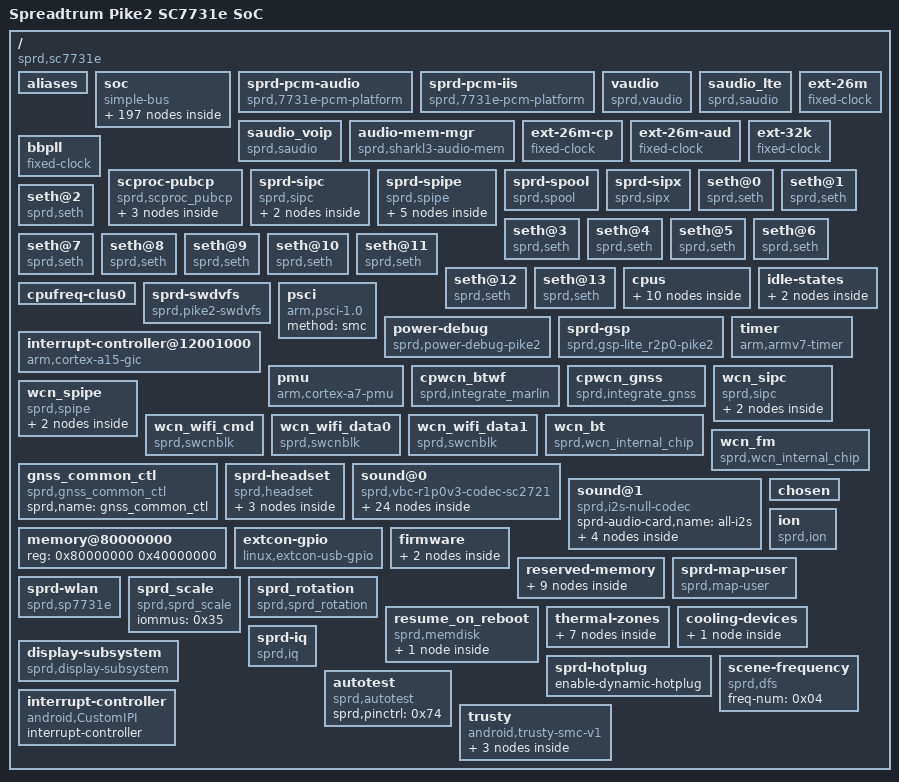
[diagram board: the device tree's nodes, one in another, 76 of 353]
/dts-v1/;

/ {
	interrupt-parent = <0x01>;
	#address-cells = <0x01>;
	#size-cells = <0x01>;
	cpuinfo_hardware = "Unisoc SC7731e";
	model = "Spreadtrum Pike2 SC7731e SoC";
	compatible = "sprd,sc7731e";
	sprd,sc-id = "sp7731e 1000 1000";

	aliases {
		serial0 = "/soc/ap-apb/serial@70000000";
		serial1 = "/soc/ap-apb/serial@70100000";
		i2c0 = "/soc/ap-apb/i2c@70500000";
		i2c1 = "/soc/ap-apb/i2c@70600000";
		i2c2 = "/soc/ap-apb/i2c@70700000";
		spi0 = "/soc/ap-apb/spi@70a00000";
		spi1 = "/soc/ap-apb/spi@70b00000";
		seth0 = "/seth@0";
		seth1 = "/seth@1";
		seth2 = "/seth@2";
		seth3 = "/seth@3";
		seth4 = "/seth@4";
		seth5 = "/seth@5";
		seth6 = "/seth@6";
		seth7 = "/seth@7";
		seth8 = "/seth@8";
		seth9 = "/seth@9";
		seth10 = "/seth@10";
		seth11 = "/seth@11";
		seth12 = "/seth@12";
		seth13 = "/seth@13";
		cooling-device0 = "/cooling-devices/cluster0-cooling";
		thm-sensor11 = "/thermal-zones/cpu-thmzone";
	};

	soc {
		compatible = "simple-bus";
		#address-cells = <0x01>;
		#size-cells = <0x01>;
		ranges;
		phandle = <0x76>;

		syscon@20e00000 {
			compatible = "syscon";
			#syscon-cells = <0x02>;
			reg = <0x20e00000 0x100000>;
			phandle = <0x0e>;
		};

		syscon@33100000 {
			compatible = "syscon";
			#syscon-cells = <0x02>;
			reg = <0x33100000 0x10000>;
			phandle = <0x58>;
		};

		syscon@40200000 {
			compatible = "syscon";
			#syscon-cells = <0x02>;
			reg = <0x40200000 0x10000>;
			phandle = <0x56>;
		};

		syscon@402b0000 {
			compatible = "syscon";
			#syscon-cells = <0x02>;
			reg = <0x402b0000 0x10000>;
			phandle = <0x1b>;
		};

		syscon@402e0000 {
			compatible = "syscon";
			#syscon-cells = <0x02>;
			reg = <0x402e0000 0x10000>;
			phandle = <0x11>;
		};

		syscon@40350000 {
			compatible = "syscon";
			#syscon-cells = <0x02>;
			reg = <0x40350000 0x3000>;
			phandle = <0x77>;
		};

		syscon@40353000 {
			compatible = "syscon";
			#syscon-cells = <0x02>;
			reg = <0x40353000 0x3000>;
			phandle = <0x78>;
		};

		syscon@40356000 {
			compatible = "syscon";
			#syscon-cells = <0x02>;
			reg = <0x40356000 0x3000>;
			phandle = <0x79>;
		};

		syscon@40359000 {
			compatible = "syscon";
			#syscon-cells = <0x02>;
			reg = <0x40359000 0x3000>;
			phandle = <0x7a>;
		};

		syscon@60100000 {
			compatible = "syscon";
			#syscon-cells = <0x02>;
			reg = <0x60100000 0x100000>;
			phandle = <0x50>;
		};

		syscon@60d00000 {
			compatible = "syscon";
			#syscon-cells = <0x02>;
			reg = <0x60d00000 0x100000>;
			phandle = <0x31>;
		};

		syscon@71300000 {
			compatible = "syscon";
			#syscon-cells = <0x02>;
			reg = <0x71300000 0x100000>;
			phandle = <0x08>;
		};

		syscon@71400000 {
			compatible = "syscon";
			#syscon-cells = <0x02>;
			reg = <0x71400000 0x100000>;
			phandle = <0x3b>;
		};

		syscon@71500000 {
			compatible = "syscon";
			#syscon-cells = <0x02>;
			reg = <0x71500000 0x100000>;
			phandle = <0x3c>;
		};

		syscon@71600000 {
			compatible = "syscon";
			#syscon-cells = <0x02>;
			reg = <0x71600000 0x100000>;
			phandle = <0x3d>;
		};

		syscon@71700000 {
			compatible = "syscon";
			#syscon-cells = <0x02>;
			reg = <0x71700000 0x100000>;
			phandle = <0x3e>;
		};

		ap-apb {
			compatible = "simple-bus";
			#address-cells = <0x01>;
			#size-cells = <0x01>;
			ranges;

			serial@70000000 {
				compatible = "sprd,sc7731-uart\0sprd,sc9836-uart";
				reg = <0x70000000 0x100>;
				interrupts = <0x00 0x02 0x04>;
				clock-names = "enable\0uart\0source";
				clocks = <0x02 0x06 0x03 0x09 0x04>;
				status = "disabled";
				phandle = <0x7b>;
			};

			serial@70100000 {
				compatible = "sprd,sc7731-uart\0sprd,sc9836-uart";
				reg = <0x70100000 0x100>;
				interrupts = <0x00 0x03 0x04>;
				clock-names = "enable\0uart\0source";
				clocks = <0x02 0x07 0x03 0x0a 0x04>;
				status = "okay";
				phandle = <0x7c>;
			};

			i2c@70500000 {
				compatible = "sprd,pike2-i2c";
				reg = <0x70500000 0x1000>;
				interrupts = <0x00 0x0b 0x04>;
				clock-names = "enable\0i2c\0source";
				clock-frequency = <0x186a0>;
				#address-cells = <0x01>;
				#size-cells = <0x00>;
				status = "disabled";
				clocks = <0x02 0x03 0x03 0x0b 0x04>;
				phandle = <0x7d>;
			};

			i2c@70600000 {
				compatible = "sprd,pike2-i2c";
				reg = <0x70600000 0x1000>;
				interrupts = <0x00 0x0c 0x04>;
				clock-names = "enable\0i2c\0source";
				clock-frequency = <0x186a0>;
				#address-cells = <0x01>;
				#size-cells = <0x00>;
				status = "disabled";
				clocks = <0x02 0x04 0x03 0x0c 0x04>;
				phandle = <0x7e>;
			};

			i2c@70700000 {
				compatible = "sprd,pike2-i2c";
				reg = <0x70700000 0x1000>;
				interrupts = <0x00 0x0d 0x04>;
				clock-names = "enable\0i2c\0source";
				clock-frequency = <0x186a0>;
				#address-cells = <0x01>;
				#size-cells = <0x00>;
				status = "disabled";
				clocks = <0x02 0x05 0x03 0x0d 0x04>;
				phandle = <0x7f>;
			};

			spi@70a00000 {
				compatible = "sprd,sc9860-spi\0sprd,pike2-spi";
				reg = <0x70a00000 0x1000>;
				interrupts = <0x00 0x07 0x04>;
				#address-cells = <0x01>;
				#size-cells = <0x00>;
				status = "disabled";
				clock-names = "enable\0spi\0source";
				clocks = <0x02 0x02 0x03 0x0e 0x04>;
				phandle = <0x80>;
			};

			spi@70b00000 {
				compatible = "sprd,sc9860-spi\0sprd,pike2-spi";
				reg = <0x70b00000 0x1000>;
				interrupts = <0x00 0x08 0x04>;
				#address-cells = <0x01>;
				#size-cells = <0x00>;
				status = "okay";
				clock-names = "enable\0spi\0source";
				clocks = <0x05 0x5f 0x06 0x18 0x07 0x03>;
				phandle = <0x81>;
			};

			i2s@70d00000 {
				compatible = "sprd,i2s";
				#sound-dai-cells = <0x00>;
				reg = <0x70d00000 0x100000>;
				sprd,dai_name = "i2s_bt_sco0";
				sprd,hw_port = <0x00>;
				sprd,syscon-ap-apb = <0x08>;
				status = "okay";
				clock-names = "clk_iis0\0clk_twpll_128m\0clk_twpll_153m6";
				clocks = <0x03 0x0f 0x07 0x0a 0x07 0x0f>;
				sprd,config_type = "pcm";
				sprd,slave_timeout = <0xf11>;
				sprd,_hw_port = <0x00>;
				sprd,fs = <0x1f40>;
				sprd,bus_type = <0x01>;
				sprd,rtx_mode = <0x03>;
				sprd,byte_per_chan = <0x01>;
				sprd,slave_mode = <0x00>;
				sprd,lsb = <0x00>;
				sprd,lrck = <0x00>;
				sprd,low_for_left = <0x01>;
				sprd,clk_inv = <0x00>;
				sprd,pcm_short_frame = <0x01>;
				sprd,pcm_slot = <0x01>;
				sprd,pcm_cycle = <0x01>;
				sprd,tx_watermark = <0x0c>;
				sprd,rx_watermark = <0x14>;
				phandle = <0x6b>;
			};
		};

		ap-ahb {
			compatible = "simple-bus";
			#address-cells = <0x01>;
			#size-cells = <0x01>;
			ranges;

			dma-controller@20100000 {
				compatible = "sprd,pike2-dma";
				reg = <0x20100000 0x4000>;
				interrupts = <0x00 0x32 0x04>;
				#dma-cells = <0x01>;
				#dma-channels = <0x1c>;
				clock-names = "enable";
				clocks = <0x09 0x04>;
				phandle = <0x52>;
			};

			usb@20200000 {
				compatible = "sprd,pike2-musb";
				reg = <0x20200000 0x2000>;
				interrupts = <0x00 0x37 0x04>;
				interrupt-names = "mc";
				clocks = <0x09 0x03>;
				clock-names = "core_clk";
				usb-phy = <0x0a>;
				phy-names = "usb";
				phandle = <0x82>;
			};

			sdio@20600000 {
				compatible = "sprd,sdhc-r10";
				reg = <0x20600000 0x1000>;
				interrupts = <0x00 0x3c 0x04>;
				clock-names = "sdio_clk\0sdio_clk_source\0sdio_ahb_enable";
				clocks = <0x06 0x17 0x07 0x02 0x09 0x08>;
				status = "okay";
				sprd,hs400es-dly = <0x45 0x7f 0x30 0x30>;
				sprd,hs400-dly = <0x45 0xaa 0x30 0x30>;
				sprd,hs200-dly = <0x7f 0xaa 0xa8 0xa8>;
				sprd,ddr52-dly = <0x48 0xf9 0x19 0x19>;
				vmmc-supply = <0x0b>;
				voltage-ranges = <0xbb8 0xbb8>;
				bus-width = <0x08>;
				non-removable;
				cap-mmc-hw-reset;
				mmc-hs400-enhanced-strobe;
				mmc-hs400-1_8v;
				mmc-hs200-1_8v;
				mmc-ddr-1_8v;
				sprd,name = "sdio_emmc";
				sprd,sdio-adma;
				no-sdio;
				no-sd;
				phandle = <0x83>;
			};

			sdio@20300000 {
				compatible = "sprd,sdhc-r10";
				reg = <0x20300000 0x1000>;
				interrupts = <0x00 0x39 0x04>;
				clock-names = "sdio_clk\0sdio_clk_source\0sdio_ahb_enable\0sdio_1x_eb\0sdio_2x_eb";
				clocks = <0x06 0x15 0x07 0x02 0x09 0x06 0x05 0x58 0x05 0x59>;
				status = "okay";
				sprd,sdr104-dly = <0x7f 0xb0 0xb4 0xb4>;
				sprd,sdr50-dly = <0x7f 0x45 0x41 0x41>;
				sprd,sdhs-dly = <0x7f 0x48 0x46 0x46>;
				vmmc-supply = <0x0c>;
				vqmmc-supply = <0x0d>;
				voltage-ranges = <0xbb8 0xbb8>;
				bus-width = <0x04>;
				sd-uhs-sdr50;
				sprd,name = "sdio_sd";
				sprd,sdio-adma;
				no-sdio;
				no-mmc;
				phandle = <0x84>;
			};

			dpu@20800000 {
				compatible = "sprd,display-processor";
				reg = <0x20800000 0x1000>;
				interrupts = <0x00 0x2e 0x04>;
				syscons = <0x0e 0x04 0x02>;
				syscon-names = "reset";
				iommus = <0x0f>;
				status = "disabled";
				dma-coherent;
				sprd,ip = "dpu-lite-r1p0";
				sprd,soc = "pike2";
				sprd,logo-memory = <0x10>;
				sprd,syscon-aon-apb = <0x11>;
				clock-names = "clk_src_96m\0clk_src_100m\0clk_src_128m\0clk_src_153m6\0clk_src_192m\0clk_src_256m\0clk_src_320m\0clk_src_384m\0clk_dpu_core\0clk_dpu_dpi\0clk_ap_ahb_disp_eb";
				clocks = <0x07 0x04 0x07 0x1e 0x07 0x0a 0x07 0x0f 0x07 0x03 0x07 0x09 0x07 0x18 0x07 0x02 0x03 0x04 0x03 0x05 0x09 0x01>;
				phandle = <0x85>;

				port {
					phandle = <0x71>;

					endpoint {
						remote-endpoint = <0x12>;
						phandle = <0x14>;
					};
				};
			};

			iommu@20800800 {
				compatible = "sprd,iommuex-dispc";
				reg = <0x20800800 0x60>;
				sprd,iova-base = <0x30000000>;
				sprd,iova-size = <0x8000000>;
				reg_name = "mmu_reg";
				status = "okay";
				#iommu-cells = <0x00>;
				phandle = <0x0f>;
			};

			dsi@21800000 {
				compatible = "sprd,dsi-host";
				reg = <0x21800000 0x1000>;
				interrupts = <0x00 0x30 0x04 0x00 0x31 0x04>;
				syscons = <0x0e 0x04 0x01>;
				syscon-names = "reset";
				status = "okay";
				sprd,ip = "sprd,dsi-ctrl\0r3p0";
				sprd,soc = "pike2";
				clock-names = "clk_ap_ahb_dsi_eb";
				clocks = <0x09 0x00>;
				#address-cells = <0x01>;
				#size-cells = <0x00>;
				phandle = <0x86>;

				ports {
					#address-cells = <0x01>;
					#size-cells = <0x00>;

					port@0 {
						reg = <0x00>;

						endpoint {
							remote-endpoint = <0x13>;
							phandle = <0x17>;
						};
					};

					port@1 {
						reg = <0x01>;

						endpoint {
							remote-endpoint = <0x14>;
							phandle = <0x12>;
						};
					};
				};

				panel {
					compatible = "sprd,generic-mipi-panel";
					#address-cells = <0x01>;
					#size-cells = <0x00>;
					reg = <0x00>;
					phandle = <0x87>;

					port@1 {
						reg = <0x01>;

						endpoint {
							remote-endpoint = <0x15>;
							phandle = <0x16>;
						};
					};
				};
			};

			dphy {
				compatible = "sprd,dsi-phy";
				#address-cells = <0x01>;
				#size-cells = <0x00>;
				reg = <0x21800000 0x1000>;
				syscons = <0x11 0x40 0x03 0x11 0x24 0x8000 0x11 0x24 0x4000 0x11 0x24 0x04 0x11 0x1a4 0x04>;
				syscon-names = "enable\0power_small\0power_large\0power_shutdown\0power_iso";
				status = "okay";
				sprd,ip = "sprd,megacores-sharkle";
				sprd,soc = "pike2";
				phandle = <0x88>;

				port@0 {
					reg = <0x00>;

					endpoint {
						remote-endpoint = <0x16>;
						phandle = <0x15>;
					};
				};

				port@1 {
					reg = <0x01>;

					endpoint {
						remote-endpoint = <0x17>;
						phandle = <0x13>;
					};
				};
			};

			gsp@20a00000 {
				compatible = "sprd,gsp-core";
				reg = <0x20a00000 0x1000>;
				core-id = <0x00>;
				kcfg-num = <0x10>;
				interrupts = <0x00 0x33 0x04>;
				iommus = <0x18>;
				clock-names = "clk_gsp\0clk_gsp_parent\0clk_gsp_eb";
				clocks = <0x03 0x03 0x07 0x02 0x09 0x02>;
				phandle = <0x57>;
			};

			iommu@20a00804 {
				compatible = "sprd,iommuex-gsp";
				reg = <0x20a00804 0x80>;
				sprd,iova-base = <0x20000000>;
				sprd,iova-size = <0x10000000>;
				reg_name = "mmu_reg";
				status = "ok";
				#iommu-cells = <0x00>;
				phandle = <0x18>;
			};

			hsphy@20e00000 {
				compatible = "sprd,pike2-phy";
				reg = <0x20e00000 0x3030>;
				reg-names = "phy_glb_regs";
				sprd,syscon-enable = <0x11>;
				sprd,tune-value = <0x5af33>;
				sprd,vdd-voltage = <0x325aa0>;
				#phy-cells = <0x00>;
				vdd-supply = <0x19>;
				extcon = <0x1a>;
				phandle = <0x0a>;
			};
		};

		aon {
			compatible = "simple-bus";
			#address-cells = <0x01>;
			#size-cells = <0x01>;
			ranges;

			audio-codec@40000000 {
				compatible = "sprd,sharkl3-audio-codec";
				reg = <0x40000000 0x2000>;
				sprd,def-da-fs = <0xac44>;
				interrupts = <0x00 0x14 0x00>;
				sprd,syscon-aon-apb = <0x11>;
				phandle = <0x29>;
			};

			vbc@40020000 {
				compatible = "sprd,vbc-r1p0v3";
				#sound-dai-cells = <0x01>;
				reg = <0x40020000 0x10000>;
				sprd,clk-stable = <0x402d0060 0x04>;
				sprd,syscon-aon-apb = <0x11>;
				sprd,syscon-pmu-apb = <0x1b>;
				sprd,dynamic-eq-support = <0x00>;
				sprd,vbc-iis-lr-invert = <0x00 0x01 0x01>;
				sprd,vbc-use-dma-type = <0x00 0x00 0x01 0x01>;
				sprd,iis_not_set_same_num = <0x01>;
				sprd,vbc-use-ad01-only = <0x01>;
				pinctrl-names = "ap_iis0_0\0pubcp_iis0_0\0tgdsp_iis0_0\0vbc_iis2_0\0ap_iis0_1\0pubcp_iis0_1\0tgdsp_iis0_1\0vbc_iis1_1";
				pinctrl-0 = <0x1c>;
				pinctrl-1 = <0x1d>;
				pinctrl-2 = <0x1e>;
				pinctrl-3 = <0x1f>;
				pinctrl-4 = <0x20>;
				pinctrl-5 = <0x21>;
				pinctrl-6 = <0x22>;
				pinctrl-7 = <0x23>;
				phandle = <0x67>;
			};

			timer@40040000 {
				compatible = "sprd,sysfrt-timer";
				reg = <0x40040000 0x10>;
				clocks = <0x24>;
				phandle = <0x89>;
			};

			timer@40050000 {
				compatible = "sprd,pike2-timer";
				reg = <0x40050000 0x14>;
				interrupts = <0x00 0x1c 0x04>;
				clocks = <0x24>;
			};

			timer@40050020 {
				compatible = "sprd,pike2-suspend-timer";
				reg = <0x40050020 0x14>;
				clocks = <0x24>;
			};

			hwspinlock@40060000 {
				compatible = "sprd,hwspinlock-r3p0";
				reg = <0x40060000 0x10000>;
				#hwlock-cells = <0x01>;
				clock-names = "enable";
				clocks = <0x05 0x12>;
				phandle = <0x25>;
			};

			mailbox@400a0000 {
				compatible = "sprd,mailbox";
				reg = <0x400a0000 0x8000 0x400a8000 0x8000>;
				syscons = <0x11 0x04 0x200000>;
				syscon-names = "clk";
				interrupts = <0x00 0x44 0x04 0x00 0x45 0x04>;
				sprd,core-cnt = <0x06>;
				sprd,version = <0x102>;
				phandle = <0x8a>;
			};

			dma-controller@40100000 {
				compatible = "sprd,pike2-dma";
				reg = <0x40100000 0x4000>;
				#dma-cells = <0x01>;
				#dma-channels = <0x0d>;
				clock-names = "enable";
				clocks = <0x05 0x2d>;
				phandle = <0x51>;
			};

			pwm@40260000 {
				compatible = "sprd,pike2-pwm\0sprd,sharkl5-pwm";
				reg = <0x40260000 0x10000>;
				clock-names = "clk_parent\0clk_pwm0\0clk_pwm0_eb\0clk_pwm1\0clk_pwm1_eb\0clk_pwm2\0clk_pwm2_eb";
				clocks = <0x04 0x06 0x03 0x05 0x01 0x06 0x04 0x05 0x02 0x06 0x05 0x05 0x03>;
				#pwm-cells = <0x02>;
				status = "okay";
				phandle = <0x8b>;
			};

			watchdog@40310000 {
				compatible = "sprd,pike2-wdt\0sprd,sharkl3-wdt";
				reg = <0x40310000 0x10000>;
				interrupts = <0x00 0x7c 0x04>;
				timeout-sec = <0x0c>;
				clock-names = "enable\0rtc_enable";
				clocks = <0x05 0x23 0x05 0x3e>;
			};

			spi@403c0000 {
				compatible = "sprd,pike2-adi";
				reg = <0x403c0000 0x10000>;
				hwlocks = <0x25 0x00>;
				#address-cells = <0x01>;
				#size-cells = <0x00>;
				sprd,hw-channels = <0x03 0x8c68 0x21 0x8c20 0x23 0x8cc0 0x24 0x8ccc>;
				phandle = <0x8c>;

				pmic@0 {
					compatible = "sprd,sc2720";
					reg = <0x00>;
					spi-max-frequency = <0x18cba80>;
					interrupts = <0x00 0x26 0x04>;
					interrupt-controller;
					#interrupt-cells = <0x02>;
					#address-cells = <0x01>;
					#size-cells = <0x00>;
					phandle = <0x26>;

					watchdog@40 {
						compatible = "sprd,sc2720-wdt\0sprd,sc27xx-wdt";
						reg = <0x40>;
						phandle = <0x8d>;
					};

					led-controller@180 {
						compatible = "sprd,sc27xx-bltc\0sprd,sc2721-bltc\0sprd,sc2720-bltc";
						#address-cells = <0x01>;
						#size-cells = <0x00>;
						reg = <0x180>;

						led@0 {
							label = "red";
							reg = <0x00>;
						};

						led@1 {
							label = "green";
							reg = <0x01>;
						};

						led@2 {
							label = "blue";
							reg = <0x02>;
						};
					};

					flash@1f4 {
						compatible = "sprd,sc27xx-flash\0sprd,sc2720-flash";
						torch-led-idx = <0x01>;
						flash-idx = <0x01>;
						reg = <0x1f4>;
						status = "okay";
						phandle = <0x8e>;
					};

					rtc@200 {
						compatible = "sprd,sc27xx-rtc\0sprd,sc2720-rtc\0sprd,sc2721-rtc";
						reg = <0x200>;
						interrupt-parent = <0x26>;
						interrupts = <0x01 0x04>;
					};

					gpio-controller@280 {
						compatible = "sprd,sc27xx-eic\0sprd,sc2720-eic";
						reg = <0x280>;
						interrupt-parent = <0x26>;
						interrupts = <0x04 0x04>;
						gpio-controller;
						#gpio-cells = <0x02>;
						interrupt-controller;
						#interrupt-cells = <0x02>;
						phandle = <0x2a>;
					};

					efuse@300 {
						compatible = "sprd,sc27xx-efuse\0sprd,sc2720-efuse\0sprd,sc2731-efuse";
						reg = <0x300>;
						#address-cells = <0x01>;
						#size-cells = <0x01>;
						hwlocks = <0x25 0x0c>;
						phandle = <0x8f>;

						calib@6 {
							reg = <0x06 0x02>;
							phandle = <0x2b>;
						};

						calib@1a {
							reg = <0x1a 0x02>;
							phandle = <0x2d>;
						};

						calib@24 {
							reg = <0x24 0x02>;
							phandle = <0x27>;
						};

						calib@26 {
							reg = <0x26 0x02>;
							phandle = <0x28>;
						};

						calib@0 {
							reg = <0x00 0x02>;
							phandle = <0x61>;
						};

						calib@28 {
							reg = <0x28 0x02>;
							phandle = <0x62>;
						};

						calib@2c {
							reg = <0x2c 0x02>;
							phandle = <0x63>;
						};
					};

					adc@404 {
						compatible = "sprd,sc27xx-adc\0sprd,sc2720-adc";
						reg = <0x404>;
						interrupt-parent = <0x26>;
						interrupts = <0x00 0x04>;
						#io-channel-cells = <0x01>;
						hwlocks = <0x25 0x04>;
						nvmem-cells = <0x27 0x28>;
						nvmem-cell-names = "big_scale_calib\0small_scale_calib";
						phandle = <0x2c>;
					};

					audio-codec@700 {
						compatible = "sprd,sc2720-audio-codec\0sprd,sc27xx-audio-codec";
						#sound-dai-cells = <0x01>;
						reg = <0x700>;
						interrupts = <0x05 0x00>;
						interrupt-parent = <0x26>;
						sprd,syscon-pmu-apb = <0x1b>;
						status = "okay";
						digital-codec = <0x29>;
						phandle = <0x68>;
					};

					fgu@a00 {
						compatible = "sprd,sc27xx-fgu\0sprd,sc2720-fgu";
						reg = <0xa00>;
						bat-detect-gpio = <0x2a 0x08 0x00>;
						nvmem-cell-names = "fgu_calib";
						nvmem-cells = <0x2b>;
						io-channels = <0x2c 0x00 0x2c 0x0e 0x2c 0x04>;
						io-channel-names = "bat-temp\0charge-vol\0batt_id-vol";
						interrupt-parent = <0x26>;
						interrupts = <0x03 0x04>;
						phandle = <0x90>;
					};

					syscon@c00 {
						compatible = "sprd,sc27xx-syscon";
						reg = <0xc00 0xe18 0xe0c>;
					};

					power-controller@c00 {
						compatible = "sprd,sc27xx-regulator\0sprd,sc2720-regulator";

						DCDC_CORE {
							regulator-name = "vddcore";
							regulator-min-microvolt = <0x30d40>;
							regulator-max-microvolt = <0x185dcb>;
							regulator-ramp-delay = <0x61a8>;
							regulator-always-on;
							phandle = <0x38>;
						};

						DCDC_GEN {
							regulator-name = "vddgen";
							regulator-min-microvolt = <0x13d620>;
							regulator-max-microvolt = <0x44794c>;
							regulator-ramp-delay = <0x61a8>;
							regulator-always-on;
							phandle = <0x91>;
						};

						DCDC_WPA {
							regulator-name = "vddwpa";
							regulator-min-microvolt = <0x61a80>;
							regulator-max-microvolt = <0x368cd8>;
							regulator-ramp-delay = <0x61a8>;
							phandle = <0x92>;
						};

						LDO_AVDD18 {
							regulator-name = "avdd18";
							regulator-min-microvolt = <0x155cc0>;
							regulator-max-microvolt = <0x2160ec>;
							regulator-ramp-delay = <0x61a8>;
							regulator-always-on;
							phandle = <0x93>;
						};

						LDO_VDDCAMIO {
							regulator-name = "vddcamio";
							regulator-min-microvolt = <0x155cc0>;
							regulator-max-microvolt = <0x2160ec>;
							regulator-ramp-delay = <0x61a8>;
							phandle = <0x94>;
						};

						LDO_VDDRF18A {
							regulator-name = "vddrf18a";
							regulator-min-microvolt = <0x155cc0>;
							regulator-max-microvolt = <0x2160ec>;
							regulator-ramp-delay = <0x61a8>;
							regulator-always-on;
							phandle = <0x95>;
						};

						LDO_VDDRF18B {
							regulator-name = "vddrf18b";
							regulator-min-microvolt = <0x155cc0>;
							regulator-max-microvolt = <0x2160ec>;
							regulator-ramp-delay = <0x61a8>;
							regulator-always-on;
							phandle = <0x96>;
						};

						LDO_VDDCAMD {
							regulator-name = "vddcamd";
							regulator-min-microvolt = <0xc3500>;
							regulator-max-microvolt = <0x18392c>;
							regulator-ramp-delay = <0x61a8>;
							phandle = <0x97>;
						};

						LDO_VDDCON {
							regulator-name = "vddcon";
							regulator-min-microvolt = <0xc3500>;
							regulator-max-microvolt = <0x18392c>;
							regulator-ramp-delay = <0x61a8>;
							phandle = <0x5a>;
						};

						LDO_MEM {
							regulator-name = "vddmem";
							regulator-min-microvolt = <0xc3500>;
							regulator-max-microvolt = <0x18392c>;
							regulator-ramp-delay = <0x61a8>;
							regulator-always-on;
							phandle = <0x98>;
						};

						LDO_VDDSIM0 {
							regulator-name = "vddsim0";
							regulator-min-microvolt = <0x189ad4>;
							regulator-max-microvolt = <0x30d400>;
							regulator-ramp-delay = <0x61a8>;
							phandle = <0x99>;
						};

						LDO_VDDSIM1 {
							regulator-name = "vddsim1";
							regulator-min-microvolt = <0x189ad4>;
							regulator-max-microvolt = <0x30d400>;
							regulator-ramp-delay = <0x61a8>;
							phandle = <0x9a>;
						};

						LDO_VDDSIM2 {
							regulator-name = "vddsim2";
							regulator-min-microvolt = <0x189ad4>;
							regulator-max-microvolt = <0x30d400>;
							regulator-ramp-delay = <0x61a8>;
							phandle = <0x9b>;
						};

						LDO_VDDCAMA {
							regulator-name = "vddcama";
							regulator-min-microvolt = <0x189ad4>;
							regulator-max-microvolt = <0x30d400>;
							regulator-ramp-delay = <0x61a8>;
							phandle = <0x9c>;
						};

						LDO_VDDCAMMOT {
							regulator-name = "vddcammot";
							regulator-min-microvolt = <0x1e8480>;
							regulator-max-microvolt = <0x36bdac>;
							regulator-ramp-delay = <0x61a8>;
							phandle = <0x9d>;
						};

						LDO_VDDEMMCCORE {
							regulator-name = "vddemmccore";
							regulator-min-microvolt = <0x1e8480>;
							regulator-max-microvolt = <0x36bdac>;
							regulator-ramp-delay = <0x61a8>;
							phandle = <0x0b>;
						};

						LDO_VDDSDCORE {
							regulator-name = "vddsdcore";
							regulator-min-microvolt = <0x1e8480>;
							regulator-max-microvolt = <0x36bdac>;
							regulator-ramp-delay = <0x61a8>;
							phandle = <0x0c>;
						};

						LDO_VDDSDIO {
							regulator-name = "vddsdio";
							regulator-min-microvolt = <0x189ad4>;
							regulator-max-microvolt = <0x30d400>;
							regulator-ramp-delay = <0x61a8>;
							phandle = <0x0d>;
						};

						LDO_VDD28 {
							regulator-name = "vdd28";
							regulator-min-microvolt = <0x189ad4>;
							regulator-max-microvolt = <0x30d400>;
							regulator-ramp-delay = <0x61a8>;
							regulator-always-on;
							phandle = <0x9e>;
						};

						LDO_VDDWIFIPA {
							regulator-name = "vddwifipa";
							regulator-min-microvolt = <0x200b20>;
							regulator-max-microvolt = <0x38444c>;
							regulator-ramp-delay = <0x61a8>;
							phandle = <0x5b>;
						};

						LDO_VDDDCXO {
							regulator-name = "vdddcxo";
							regulator-min-microvolt = <0x16e360>;
							regulator-max-microvolt = <0x2f1c8c>;
							regulator-ramp-delay = <0x61a8>;
							regulator-always-on;
							phandle = <0x9f>;
						};

						LDO_VDDUSB33 {
							regulator-name = "vddusb33";
							regulator-min-microvolt = <0x200b20>;
							regulator-max-microvolt = <0x38444c>;
							regulator-ramp-delay = <0x61a8>;
							phandle = <0x19>;
						};
					};

					poweroff@c20 {
						compatible = "sprd,sc27xx-poweroff\0sprd,sc2720-poweroff";
						reg = <0xc20>;
					};

					vibrator@e00 {
						compatible = "sprd,sc27xx-vibrator\0sprd,sc2721-vibrator\0sprd,sc2720-vibrator";
						reg = <0xe00>;
					};

					charger@e0c {
						compatible = "sprd,sc27xx-charger\0sprd,sc2720-charger";
						reg = <0xe0c>;
						nvmem-cell-names = "cccv_calib";
						nvmem-cells = <0x2d>;
						status = "disabled";
						phandle = <0xa0>;
					};

					hw-reset@e68 {
						compatible = "sprd,sc27xx-7sreset\0sprd,sc2720-7sreset";
						reg = <0xe68 0xe38>;
					};
				};
			};

			gpio@40210000 {
				compatible = "sprd,pike2-eic-debounce";
				reg = <0x40210000 0x80 0x40370000 0x80>;
				gpio-controller;
				#gpio-cells = <0x02>;
				interrupt-controller;
				#interrupt-cells = <0x02>;
				interrupts = <0x00 0x25 0x04>;
				phandle = <0x6c>;
			};

			gpio@40210080 {
				compatible = "sprd,pike2-eic-latch";
				reg = <0x40210080 0x20 0x40370080 0x20>;
				gpio-controller;
				#gpio-cells = <0x02>;
				interrupt-controller;
				#interrupt-cells = <0x02>;
				interrupts = <0x00 0x25 0x04>;
				phandle = <0xa1>;
			};

			gpio@402100a0 {
				compatible = "sprd,pike2-eic-async";
				reg = <0x402100a0 0x20 0x403700a0 0x20>;
				gpio-controller;
				#gpio-cells = <0x02>;
				interrupt-controller;
				#interrupt-cells = <0x02>;
				interrupts = <0x00 0x25 0x04>;
				phandle = <0xa2>;
			};

			gpio@402100c0 {
				compatible = "sprd,pike2-eic-sync";
				reg = <0x402100c0 0x20 0x403700c0 0x20>;
				gpio-controller;
				#gpio-cells = <0x02>;
				interrupt-controller;
				#interrupt-cells = <0x02>;
				interrupts = <0x00 0x25 0x04>;
				phandle = <0xa3>;
			};

			efuse@40240000 {
				compatible = "sprd,pike2-efuse";
				reg = <0x40240000 0x10000>;
				clock-names = "enable";
				hwlocks = <0x25 0x08>;
				clocks = <0x05 0x0a>;
				phandle = <0xa4>;

				cthm-sign@20 {
					reg = <0x20 0x04>;
					bits = <0x04 0x01>;
					phandle = <0x2e>;
				};

				cthm-ratio@20 {
					reg = <0x20 0x04>;
					bits = <0x05 0x07>;
					phandle = <0x2f>;
				};

				cthm-delta@21 {
					reg = <0x21 0x04>;
					bits = <0x04 0x07>;
					phandle = <0x30>;
				};

				wcn-alpha@8 {
					reg = <0x08 0x04>;
					phandle = <0x5c>;
				};

				wcn-beta@c {
					reg = <0x0c 0x04>;
					phandle = <0x5d>;
				};

				wcn-gamma@10 {
					reg = <0x10 0x04>;
					phandle = <0x5e>;
				};

				wcn-delta@20 {
					reg = <0x20 0x04>;
					phandle = <0x60>;
				};

				dvfs-bin-cpu0@1d {
					reg = <0x1d 0x04>;
					bits = <0x00 0x04>;
					phandle = <0x55>;
				};
			};

			gpio@40280000 {
				compatible = "sprd,pike2-gpio";
				reg = <0x40280000 0x1000>;
				gpio-controller;
				#gpio-cells = <0x02>;
				interrupt-controller;
				#interrupt-cells = <0x02>;
				interrupts = <0x00 0x23 0x04>;
				phandle = <0x65>;
			};

			pinctrl@402a0000 {
				compatible = "sprd,pike2-pinctrl";
				reg = <0x402a0000 0x10000>;
				phandle = <0x74>;

				ap-iis0-0 {
					pins = "PIKE2_IIS0_SYS_SEL";
					sprd,control = <0x00>;
					phandle = <0x1c>;
				};

				tgdsp-iis0-0 {
					pins = "PIKE2_IIS0_SYS_SEL";
					sprd,control = <0x01>;
					phandle = <0x1e>;
				};

				pubcp-iis0-0 {
					pins = "PIKE2_IIS0_SYS_SEL";
					sprd,control = <0x02>;
					phandle = <0x1d>;
				};

				vbc-iis2-0 {
					pins = "PIKE2_IIS0_SYS_SEL";
					sprd,control = <0x03>;
					phandle = <0x1f>;
				};

				ap-iis0-1 {
					pins = "PIKE2_IIS1_SYS_SEL";
					sprd,control = <0x00>;
					phandle = <0x20>;
				};

				tgdsp-iis0-1 {
					pins = "PIKE2_IIS1_SYS_SEL";
					sprd,control = <0x01>;
					phandle = <0x22>;
				};

				pubcp-iis0-1 {
					pins = "PIKE2_IIS1_SYS_SEL";
					sprd,control = <0x02>;
					phandle = <0x21>;
				};

				vbc-iis1-1 {
					pins = "PIKE2_IIS1_SYS_SEL";
					sprd,control = <0x03>;
					phandle = <0x23>;
				};
			};

			thermal@402f0000 {
				compatible = "sprd,sharkl3-thermal\0sprd,pike2-thermal";
				reg = <0x402f0000 0x10000>;
				clock-names = "enable";
				clocks = <0x05 0x1c>;
				#thermal-sensor-cells = <0x01>;
				nvmem-cells = <0x2e 0x2f 0x30>;
				nvmem-cell-names = "thm_sign_cal\0thm_ratio_cal\0thm_delta_cal";
				phandle = <0x6e>;
			};

			djtag@40340000 {
				compatible = "sprd,djtag";
				reg = <0x40340000 0x1000>;
				syscon-names = "soft_rst";
				syscons = <0x11 0x130 0x80>;
				clock-names = "enable\0tck";
				clocks = <0x05 0x2b 0x05 0x26>;
				hwlocks = <0x25 0x0a>;
				hwlock-names = "djtag";
				#address-cells = <0x01>;
				#size-cells = <0x00>;
				phandle = <0xa5>;

				aon-busmonitor@3 {
					compatible = "sprd,sharkl5-busmonitor\0sprd,pike2-busmonitor";
					interrupts = <0x00 0x05 0x04 0x00 0x09 0x04 0x00 0x04 0x04 0x00 0x06 0x04>;
					reg = <0x03>;
					sprd,bm-num = <0x04>;
					sprd,bm-name = "WCN\0AP\0WTLCP\0PUBCP";
					sprd,bm-type = <0x01 0x01 0x01 0x01>;
					sprd,bm-dap = <0x01 0x02 0x03 0x04>;
					sprd,bm-config = <0x00 0x01 0x01 0x00 0x01 0x01 0x00 0x01 0x01 0x00 0x01 0x01>;
					sprd,bm-id = <0x00 0x00 0x00 0x00 0x00 0x00 0x00 0x00 0x00 0x00 0x00 0x00>;
					sprd,bm-ranges = <0x00 0x00 0x00 0x00 0x00 0x00 0x00 0x00>;
				};
			};
		};

		mm {
			compatible = "simple-bus";
			#address-cells = <0x01>;
			#size-cells = <0x01>;
			ranges;

			cam-domain {
				compatible = "sprd,cam-domain";
				sprd,aon-apb-syscon = <0x11>;
				sprd,cam-ahb-syscon = <0x31>;
				sprd,syscon-pmu-apb = <0x1b>;
				clock-names = "clk_gate_eb\0clk_mm_eb\0clk_mm_ahb\0clk_mm_ahb_parent";
				clocks = <0x32 0x05 0x05 0x14 0x33 0x00 0x07 0x0f>;
				phandle = <0xa6>;
			};

			mipi-csi-phy0 {
				compatible = "sprd,mipi-csi-phy";
				sprd,phyid = <0x00>;
				status = "disabled";
				phandle = <0xa7>;
			};

			dcam@60800000 {
				compatible = "sprd,dcam";
				reg = <0x60800000 0x4000>;
				interrupts = <0x00 0x2d 0x04>;
				sprd,cam-ahb-syscon = <0x31>;
				sprd,aon-apb-syscon = <0x11>;
				sprd,syscon-pmu-apb = <0x1b>;
				sprd,isp = <0x34>;
				sprd,dcam-count = <0x01>;
				iommus = <0x35>;
				status = "okay";
				clock-names = "dcam_eb\0clk_gate_eb\0dcam_axi_eb\0dcam_clk\0dcam_clk_parent\0dcam_axi_clk\0dcam_axi_clk_parent";
				clocks = <0x32 0x00 0x32 0x05 0x32 0x0a 0x33 0x02 0x07 0x0c 0x33 0x07 0x07 0x08>;
				phandle = <0xa8>;
			};

			iommu@60800200 {
				compatible = "sprd,iommuex-dcam";
				reg = <0x60800200 0x60>;
				sprd,frc-reg = <0x60800004>;
				sprd,iova-base = <0x40000000>;
				sprd,iova-size = <0x10000000>;
				reg_name = "mmu_reg";
				status = "okay";
				#iommu-cells = <0x00>;
				phandle = <0x35>;
			};

			isp@60a00000 {
				compatible = "sprd,isp";
				reg = <0x60a00000 0x100000>;
				interrupts = <0x00 0x2c 0x04 0x00 0x7d 0x04>;
				sprd,cam-ahb-syscon = <0x31>;
				sprd,aon-apb-syscon = <0x11>;
				sprd,isp-count = <0x01>;
				iommus = <0x36>;
				status = "okay";
				clock-names = "isp_eb\0isp_axi_eb\0isp_clk\0isp_clk_high_parent\0isp_clk_low_parent\0isp_axi_clk\0isp_axi_clk_parent";
				clocks = <0x32 0x01 0x32 0x09 0x33 0x04 0x07 0x0c 0x07 0x09 0x33 0x08 0x07 0x08>;
				phandle = <0x34>;
			};

			iommu@60a00800 {
				compatible = "sprd,iommuex-isp";
				reg = <0x60a00800 0x400>;
				sprd,iova-base = <0x50000000>;
				sprd,iova-size = <0x10000000>;
				reg_name = "mmu_reg";
				status = "okay";
				#iommu-cells = <0x00>;
				phandle = <0x36>;
			};

			jpeg-codec@60b00000 {
				compatible = "sprd,pike2-jpg";
				reg = <0x60b00000 0x8000>;
				interrupts = <0x00 0x2a 0x04>;
				syscons = <0x31 0x04 0x100 0x11 0x00 0x2000000>;
				syscon-names = "reset\0aon_apb_eb";
				iommus = <0x37>;
				status = "okay";
				clock-names = "jpg_domain_eb\0clk_vsp_mq_ahb_eb\0jpg_ckg_eb\0jpg_dev_eb\0clk_src_76m8\0clk_src_128m\0clk_src_256m\0jpg_clk";
				clocks = <0x05 0x14 0x32 0x06 0x32 0x05 0x32 0x04 0x07 0x10 0x07 0x0a 0x07 0x09 0x33 0x05>;
				phandle = <0xa9>;
			};

			iommu@60b00100 {
				compatible = "sprd,iommuex-jpg";
				reg = <0x60b00100 0x400>;
				sprd,iova-base = <0x70000000>;
				sprd,iova-size = <0x10000000>;
				reg_name = "mmu_reg";
				status = "okay";
				#iommu-cells = <0x00>;
				phandle = <0x37>;
			};

			csi@60c00000 {
				compatible = "sprd,csi-controller";
				reg = <0x60c00000 0x1000>;
				interrupts = <0x00 0x28 0x04 0x00 0x29 0x04>;
				sprd,cam-ahb-syscon = <0x31>;
				sprd,ana-apb-syscon = <0x11>;
				sprd,csi-id = <0x00>;
				sprd,ip-version = <0x100>;
				sprd,dcam-id = <0x00>;
				status = "okay";
				clock-names = "clk_mipi_csi_gate_eb\0clk_csi_eb\0clk_cphy_cfg_gate_eb\0mipi_csi_src_eb";
				clocks = <0x32 0x03 0x32 0x0b 0x32 0x07 0x33 0x06>;
				phandle = <0xaa>;
			};

			gpu@60000000 {
				compatible = "sprd,mali-midgard";
				reg = <0x60000000 0x4000>;
				gpu-supply = <0x38>;
				syscons = <0x1b 0x20 0x2000000 0x11 0x3098 0xffffffff 0x11 0x309c 0xffffffff>;
				syscon-names = "top_force_shutdown\0gpu_target_volt\0cpu_target_volt";
				interrupts = <0x00 0x27 0x04 0x00 0x27 0x04 0x00 0x27 0x04>;
				interrupt-names = "JOB\0MMU\0GPU";
				operating-points = <0x5dc00 0xdbba0 0x82208 0xdbba0 0x927c0 0xf4240>;
				sprd,dfs-lists = <0x5dc00 0xdbba0 0x06 0x01 0x82208 0xdbba0 0x08 0x01 0x927c0 0xf4240 0x08 0x01>;
				sprd,dfs-default = <0x00>;
				sprd,dfs-scene-extreme = <0x02>;
				sprd,dfs-scene-high = <0x02>;
				sprd,dfs-scene-medium = <0x01>;
				sprd,dfs-scene-low = <0x00>;
				sprd,dfs-range-max = <0x02>;
				sprd,dfs-range-min = <0x00>;
				clocks = <0x05 0x16 0x39 0x00 0x07 0x0f 0x07 0x03 0x07 0x09 0x07 0x0c 0x07 0x02 0x07 0x08 0x07 0x23>;
				phandle = <0xab>;
			};

			video-codec@60900000 {
				compatible = "sprd,pike2-vsp";
				reg = <0x60900000 0xc000>;
				interrupts = <0x00 0x2b 0x04>;
				syscons = <0x31 0x04 0x80 0x1b 0x1c 0x2000000 0x1b 0x1c 0x1000000 0x1b 0xbc 0xf0000000 0x11 0x00 0x2000000>;
				syscon-names = "reset\0pmu_vsp_force_shutdown\0pmu_vsp_auto_shutdown\0pmu_pwr_status\0vsp_domain_eb";
				iommus = <0x3a>;
				status = "okay";
				clock-names = "clk_mm_eb\0clk_vsp_mq_ahb_eb\0clk_axi_gate_vsp\0clk_ahb_gate_vsp_eb\0clk_src_128m\0clk_src_256m\0clk_src_307m2\0clk_vsp";
				clocks = <0x05 0x28 0x32 0x06 0x32 0x05 0x32 0x02 0x07 0x0a 0x07 0x09 0x07 0x0c 0x33 0x03>;
				phandle = <0xac>;
			};

			iommu@60901140 {
				compatible = "sprd,iommuex-vsp";
				reg = <0x60901140 0x60>;
				sprd,iova-base = <0x20000000>;
				sprd,iova-size = <0x10000000>;
				reg_name = "mmu_reg";
				status = "okay";
				#iommu-cells = <0x00>;
				phandle = <0x3a>;
			};
		};

		sprd-sleep {
			compatible = "sprd,pike2-sleep";
			sprd,sys-ap-ahb = <0x0e>;
			sprd,sys-ap-apb = <0x08>;
			sprd,sys-aon-apb = <0x11>;
			sprd,sys-pmu-apb = <0x1b>;
			sprd,sys-ap-intc0 = <0x3b>;
			sprd,sys-ap-intc1 = <0x3c>;
			sprd,sys-ap-intc2 = <0x3d>;
			sprd,sys-ap-intc3 = <0x3e>;
		};

		pub {
			compatible = "simple-bus";
			#address-cells = <0x01>;
			#size-cells = <0x01>;
			ranges;

			dmc-controller@30000000 {
				compatible = "sprd,pike2-dmc";
				reg = <0x30000000 0x1000>;
				phandle = <0xad>;
			};
		};

		funnel-soc@10001000 {
			compatible = "arm,coresight-funnel\0arm,primecell";
			reg = <0x10001000 0x1000>;
			clocks = <0x04>;
			clock-names = "apb_pclk";
			phandle = <0xae>;

			ports {
				#address-cells = <0x01>;
				#size-cells = <0x00>;

				port@0 {
					reg = <0x00>;

					endpoint {
						remote-endpoint = <0x3f>;
						phandle = <0x41>;
					};
				};

				port@1 {
					reg = <0x00>;

					endpoint {
						slave-mode;
						remote-endpoint = <0x40>;
						phandle = <0x42>;
					};
				};
			};
		};

		tmc-etb@10003000 {
			compatible = "arm,coresight-tmc\0arm,primecell";
			reg = <0x10003000 0x1000>;
			clocks = <0x04>;
			clock-names = "apb_pclk";
			phandle = <0xaf>;

			port {

				endpoint {
					slave-mode;
					remote-endpoint = <0x41>;
					phandle = <0x3f>;
				};
			};
		};

		cs-ts@10009000 {
			compatible = "arm,coresight-ts\0arm,primecell";
			reg = <0x10009000 0x1000>;
			phandle = <0xb0>;
		};

		funnel-core@10220000 {
			compatible = "arm,coresight-funnel\0arm,primecell";
			reg = <0x10220000 0x1000>;
			clocks = <0x04>;
			clock-names = "apb_pclk";
			phandle = <0xb1>;

			ports {
				#address-cells = <0x01>;
				#size-cells = <0x00>;

				port@0 {
					reg = <0x00>;

					endpoint {
						remote-endpoint = <0x42>;
						phandle = <0x40>;
					};
				};

				port@1 {
					reg = <0x00>;

					endpoint {
						slave-mode;
						remote-endpoint = <0x43>;
						phandle = <0x48>;
					};
				};

				port@2 {
					reg = <0x01>;

					endpoint {
						slave-mode;
						remote-endpoint = <0x44>;
						phandle = <0x4a>;
					};
				};

				port@3 {
					reg = <0x02>;

					endpoint {
						slave-mode;
						remote-endpoint = <0x45>;
						phandle = <0x4c>;
					};
				};

				port@4 {
					reg = <0x03>;

					endpoint {
						slave-mode;
						remote-endpoint = <0x46>;
						phandle = <0x4e>;
					};
				};
			};
		};

		etm-core0@1025c000 {
			compatible = "arm,coresight-etm3x\0arm,primecell";
			reg = <0x1025c000 0x1000>;
			cpu = <0x47>;
			clocks = <0x06 0x01 0x06 0x13 0x07 0x08>;
			clock-names = "apb_pclk\0clk_cs\0cs_src";
			phandle = <0xb2>;

			port {

				endpoint {
					remote-endpoint = <0x48>;
					phandle = <0x43>;
				};
			};
		};

		etm-core1@1025d000 {
			compatible = "arm,coresight-etm3x\0arm,primecell";
			reg = <0x1025d000 0x1000>;
			cpu = <0x49>;
			clocks = <0x06 0x01 0x06 0x13 0x07 0x08>;
			clock-names = "apb_pclk\0clk_cs\0cs_src";
			phandle = <0xb3>;

			port {

				endpoint {
					remote-endpoint = <0x4a>;
					phandle = <0x44>;
				};
			};
		};

		etm-core2@1025e000 {
			compatible = "arm,coresight-etm3x\0arm,primecell";
			reg = <0x1025e000 0x1000>;
			cpu = <0x4b>;
			clocks = <0x06 0x01 0x06 0x13 0x07 0x08>;
			clock-names = "apb_pclk\0clk_cs\0cs_src";
			phandle = <0xb4>;

			port {

				endpoint {
					remote-endpoint = <0x4c>;
					phandle = <0x45>;
				};
			};
		};

		etm-core3@1025f000 {
			compatible = "arm,coresight-etm3x\0arm,primecell";
			reg = <0x1025f000 0x1000>;
			cpu = <0x4d>;
			clocks = <0x06 0x01 0x06 0x13 0x07 0x08>;
			clock-names = "apb_pclk\0clk_cs\0cs_src";
			phandle = <0xb5>;

			port {

				endpoint {
					remote-endpoint = <0x4e>;
					phandle = <0x46>;
				};
			};
		};

		pmu-gate {
			compatible = "sprd,sc7731e-pmu-gate";
			sprd,syscon = <0x1b>;
			clocks = <0x04>;
			#clock-cells = <0x01>;
			phandle = <0x4f>;
		};

		pll {
			compatible = "sprd,sc7731e-pll";
			sprd,syscon = <0x11>;
			clocks = <0x4f 0x00>;
			#clock-cells = <0x01>;
			phandle = <0x07>;
		};

		apahb-gate {
			compatible = "sprd,sc7731e-apahb-gate";
			sprd,syscon = <0x0e>;
			clocks = <0x03 0x00>;
			#clock-cells = <0x01>;
			phandle = <0x09>;
		};

		clock-controller@21500000 {
			compatible = "sprd,sc7731e-ap-clk";
			reg = <0x21500000 0x1000>;
			clocks = <0x04>;
			#clock-cells = <0x01>;
			phandle = <0x03>;
		};

		clock-controller@402d0000 {
			compatible = "sprd,sc7731e-aon-clk";
			reg = <0x402d0000 0x1000>;
			clocks = <0x04>;
			#clock-cells = <0x01>;
			phandle = <0x06>;
		};

		aonapb-gate {
			compatible = "sprd,sc7731e-aonapb-gate";
			sprd,syscon = <0x11>;
			clocks = <0x06 0x01>;
			#clock-cells = <0x01>;
			phandle = <0x05>;
		};

		clock-controller@60100000 {
			compatible = "sprd,sc7731e-gpu-clk";
			sprd,syscon = <0x50>;
			syscons = <0x11 0x00 0x8000000 0x1b 0x20 0x2000000>;
			syscon-names = "enable\0power";
			clocks = <0x04>;
			#clock-cells = <0x01>;
			phandle = <0x39>;
		};

		clock-controller@60e00000 {
			compatible = "sprd,sc7731e-mm-clk";
			reg = <0x60e00000 0x1000>;
			clocks = <0x06 0x00>;
			#clock-cells = <0x01>;
			phandle = <0x33>;
		};

		mm-gate {
			compatible = "sprd,sc7731e-mm-gate";
			sprd,syscon = <0x31>;
			syscons = <0x11 0x00 0x2000000 0x1b 0x1c 0x2000000>;
			syscon-names = "enable\0power";
			clocks = <0x06 0x00>;
			#clock-cells = <0x01>;
			phandle = <0x32>;
		};

		apapb-gate {
			compatible = "sprd,sc7731e-apapb-gate";
			sprd,syscon = <0x08>;
			clocks = <0x04>;
			#clock-cells = <0x01>;
			phandle = <0x02>;
		};
	};

	sprd-pcm-audio {
		compatible = "sprd,7731e-pcm-platform\0sprd,sharkl3-pcm-platform";
		#sound-dai-cells = <0x00>;
		dmas = <0x51 0x01 0x51 0x02 0x51 0x03 0x51 0x04 0x51 0x05 0x51 0x06 0x51 0x07 0x51 0x08 0x52 0x01 0x52 0x02 0x52 0x03 0x52 0x04>;
		dma-names = "da01-l\0da01-r\0da23-l\0da23-r\0normal-2stage-p\0normal-2stage-c\0deep-2stage-p\0ad23-2stage-c\0ad01-l\0ad01-r\0ad23-l\0ad23-r";
		sprd,dma-2stage-usecase = <0x02>;
		sprd,node-count-2stage-level-1 = <0x01>;
		sprd,syscon-pmu-apb = <0x1b>;
		sprd,dma-2stage-level-1-int-source = <0x01>;
		phandle = <0x66>;
	};

	sprd-pcm-iis {
		compatible = "sprd,7731e-pcm-platform\0sprd,sharkl3-pcm-platform";
		#sound-dai-cells = <0x00>;
		dmas = <0x52 0x05 0x52 0x06 0x52 0x07 0x52 0x08 0x52 0x09 0x52 0x0a 0x52 0x0b 0x52 0x0c>;
		dma-names = "iis0_tx\0iis0_rx\0iis1_tx\0iis1_rx\0iis2_tx\0iis2_rx\0iis3_tx\0iis3_rx";
		sprd,dma-2stage-usecase = <0x02>;
		sprd,node-count-2stage-level-1 = <0x01>;
		sprd,syscon-pmu-apb = <0x1b>;
		sprd,dma-2stage-level-1-int-source = <0x01>;
		phandle = <0x6a>;
	};

	vaudio {
		compatible = "sprd,vaudio";
		#sound-dai-cells = <0x01>;
		phandle = <0x69>;
	};

	saudio_lte {
		compatible = "sprd,saudio";
		sprd,saudio-dst-id = <0x05>;
		sprd,ctrl_channel = <0x0a>;
		sprd,playback_channel = <0x0b 0x83 0x84>;
		sprd,capture_channel = <0x0c>;
		sprd,monitor_channel = <0x0d>;
		sprd,device = <0x03>;
		sprd,saudio-names = "saudiolte";
	};

	saudio_voip {
		compatible = "sprd,saudio";
		sprd,saudio-dst-id = <0x05>;
		sprd,ctrl_channel = <0x0e>;
		sprd,playback_channel = <0x0f 0x97>;
		sprd,capture_channel = <0x10>;
		sprd,monitor_channel = <0x11>;
		sprd,device = <0x02>;
		sprd,saudio-names = "saudiovoip";
	};

	audio-mem-mgr {
		compatible = "sprd,sharkl3-audio-mem\0sprd,pike2-audio-mem";
		sprd,iram_phy_addr = <0x50000000 0xb000>;
		sprd,iram_normal = <0x50000000 0x00>;
		sprd,iram_deepbuf = <0x50000000 0xa000>;
		sprd,iram_4arm7 = <0x5000a000 0x1000>;
	};

	ext-26m {
		compatible = "fixed-clock";
		#clock-cells = <0x00>;
		clock-frequency = <0x18cba80>;
		clock-output-names = "ext-26m";
		phandle = <0x04>;
	};

	ext-26m-cp {
		compatible = "fixed-clock";
		#clock-cells = <0x00>;
		clock-frequency = <0x18cba80>;
		clock-output-names = "ext-26m-cp";
		phandle = <0xb6>;
	};

	ext-26m-aud {
		compatible = "fixed-clock";
		#clock-cells = <0x00>;
		clock-frequency = <0x18cba80>;
		clock-output-names = "ext-26m-aud";
		phandle = <0xb7>;
	};

	ext-32k {
		compatible = "fixed-clock";
		#clock-cells = <0x00>;
		clock-frequency = <0x8000>;
		clock-output-names = "ext-32k";
		phandle = <0x24>;
	};

	bbpll {
		compatible = "fixed-clock";
		#clock-cells = <0x00>;
		clock-frequency = <0x4a62f800>;
		clock-output-names = "bbpll";
		phandle = <0xb8>;
	};

	scproc-pubcp {
		compatible = "sprd,scproc_pubcp";
		#address-cells = <0x01>;
		#size-cells = <0x01>;
		ranges;

		scproc@50800000 {
			sprd,name = "pmic";
			syscons = <0x11 0xff 0x00 0x1b 0xff 0x200000 0x11 0x114 0x01 0x11 0xff 0x00 0x11 0xff 0x00>;
			syscon-names = "shutdown\0deepsleep\0corereset\0sysreset\0getstatus";
			reg = <0x50800000 0x10000>;
			#address-cells = <0x01>;
			#size-cells = <0x01>;
			ranges = <0x00 0x50800000 0x10000>;
			phandle = <0xb9>;

			pm-sys@0 {
				cproc,name = "pm_sys";
				reg = <0x00 0x10000>;
			};
		};

		scproc@5000d000 {
			sprd,decoup = "cproc-use-decoup";
			sprd,name = "cptl";
			syscons = <0x1b 0x48 0x2000000 0x1b 0xcc 0x40000 0x11 0x284 0x400 0x1b 0xb0 0x02 0x11 0xff 0x00 0x11 0x130 0x20000>;
			syscon-names = "shutdown\0deepsleep\0corereset\0sysreset\0getstatus\0dspreset";
			reg = <0x5000d000 0x1000>;
			interrupts = <0x00 0x53 0x00>;
			phandle = <0xba>;
		};
	};

	sprd-sipc {
		compatible = "sprd,sipc";

		sipc@89400000 {
			sprd,name = "sipc-lte";
			sprd,dst = <0x05 0x02>;
			sprd,smem-info = <0x89400000 0x89400000 0x200000>;
			phandle = <0xbb>;
		};

		sipc@5000b000 {
			sprd,name = "sipc-pmsys";
			sprd,dst = <0x06 0x01>;
			sprd,smem-info = <0x5000b000 0x2000b000 0x800>;
			phandle = <0xbc>;
		};
	};

	sprd-spipe {
		compatible = "sprd,spipe";

		spipe@0 {
			sprd,name = "slog_pm";
			sprd,dst = <0x06>;
			sprd,channel = <0x05>;
			sprd,ringnr = <0x01>;
			sprd,size-rxbuf = <0x5b0>;
			sprd,size-txbuf = <0x100>;
		};

		spipe@1 {
			sprd,name = "sctl_pm";
			sprd,dst = <0x06>;
			sprd,channel = <0x06>;
			sprd,ringnr = <0x01>;
			sprd,size-rxbuf = <0xc0>;
			sprd,size-txbuf = <0x40>;
		};

		spipe@2 {
			sprd,name = "spipe_lte";
			sprd,dst = <0x05>;
			sprd,channel = <0x04>;
			sprd,ringnr = <0x0f>;
			sprd,size-rxbuf = <0x1000>;
			sprd,size-txbuf = <0x1000>;
		};

		spipe@3 {
			sprd,name = "sdiag_lte";
			sprd,dst = <0x05>;
			sprd,channel = <0x15>;
			sprd,ringnr = <0x01>;
			sprd,size-rxbuf = <0x20000>;
			sprd,size-txbuf = <0x8000>;
		};

		spipe@4 {
			sprd,name = "stty_lte";
			sprd,dst = <0x05>;
			sprd,channel = <0x06>;
			sprd,ringnr = <0x20>;
			sprd,size-rxbuf = <0x800>;
			sprd,size-txbuf = <0x800>;
		};
	};

	sprd-spool {
		compatible = "sprd,spool";
		sprd,name = "slog_lte";
		sprd,dst = <0x05>;
		sprd,channel = <0x05>;
		sprd,tx-blksize = <0x00>;
		sprd,tx-blknum = <0x00>;
		sprd,rx-blksize = <0x10000>;
		sprd,rx-blknum = <0x04>;
	};

	sprd-sipx {
		compatible = "sprd,sipx";
		sprd,name = "sipx_lte";
		sprd,dst = <0x05>;
		sprd,dl-pool = <0x80>;
		sprd,dl-ack-pool = <0x00>;
		sprd,ul-pool = <0x100>;
		sprd,ul-ack-pool = <0x100>;
	};

	seth@0 {
		compatible = "sprd,seth";
		sprd,dst = <0x05>;
		sprd,channel = <0x07>;
		sprd,blknum = <0x100>;
		phandle = <0xbd>;
	};

	seth@1 {
		compatible = "sprd,seth";
		sprd,dst = <0x05>;
		sprd,channel = <0x08>;
		sprd,blknum = <0x100>;
		phandle = <0xbe>;
	};

	seth@2 {
		compatible = "sprd,seth";
		sprd,dst = <0x05>;
		sprd,channel = <0x09>;
		sprd,blknum = <0x100>;
		phandle = <0xbf>;
	};

	seth@3 {
		compatible = "sprd,seth";
		sprd,dst = <0x05>;
		sprd,channel = <0x12>;
		sprd,blknum = <0x100>;
		phandle = <0xc0>;
	};

	seth@4 {
		compatible = "sprd,seth";
		sprd,dst = <0x05>;
		sprd,channel = <0x13>;
		sprd,blknum = <0x100>;
		phandle = <0xc1>;
	};

	seth@5 {
		compatible = "sprd,seth";
		sprd,dst = <0x05>;
		sprd,channel = <0x14>;
		sprd,blknum = <0x100>;
		phandle = <0xc2>;
	};

	seth@6 {
		compatible = "sprd,seth";
		sprd,dst = <0x05>;
		sprd,channel = <0x18>;
		sprd,blknum = <0x100>;
		phandle = <0xc3>;
	};

	seth@7 {
		compatible = "sprd,seth";
		sprd,dst = <0x05>;
		sprd,channel = <0x19>;
		sprd,blknum = <0x100>;
		phandle = <0xc4>;
	};

	seth@8 {
		compatible = "sprd,seth";
		sprd,dst = <0x05>;
		sprd,channel = <0x1a>;
		sprd,blknum = <0x100>;
		phandle = <0xc5>;
	};

	seth@9 {
		compatible = "sprd,seth";
		sprd,dst = <0x05>;
		sprd,channel = <0x1b>;
		sprd,blknum = <0x100>;
		phandle = <0xc6>;
	};

	seth@10 {
		compatible = "sprd,seth";
		sprd,dst = <0x05>;
		sprd,channel = <0x1c>;
		sprd,blknum = <0x100>;
		phandle = <0xc7>;
	};

	seth@11 {
		compatible = "sprd,seth";
		sprd,dst = <0x05>;
		sprd,channel = <0x1d>;
		sprd,blknum = <0x100>;
		phandle = <0xc8>;
	};

	seth@12 {
		compatible = "sprd,seth";
		sprd,dst = <0x05>;
		sprd,channel = <0x1e>;
		sprd,blknum = <0x100>;
		phandle = <0xc9>;
	};

	seth@13 {
		compatible = "sprd,seth";
		sprd,dst = <0x05>;
		sprd,channel = <0x1f>;
		sprd,blknum = <0x100>;
		phandle = <0xca>;
	};

	cpus {
		#address-cells = <0x01>;
		#size-cells = <0x00>;

		cpu-map {

			cluster0 {

				core0 {
					cpu = <0x47>;
				};

				core1 {
					cpu = <0x49>;
				};

				core2 {
					cpu = <0x4b>;
				};

				core3 {
					cpu = <0x4d>;
				};
			};
		};

		cpu@0 {
			device_type = "cpu";
			compatible = "arm,cortex-a7";
			enable-method = "psci";
			reg = <0x00>;
			cpufreq-data-v1 = <0x53>;
			cpu-idle-states = <0x54>;
			cpu-supply = <0x38>;
			phandle = <0x47>;
		};

		cpu@1 {
			device_type = "cpu";
			compatible = "arm,cortex-a7";
			enable-method = "psci";
			reg = <0x01>;
			cpufreq-data-v1 = <0x53>;
			cpu-idle-states = <0x54>;
			cpu-supply = <0x38>;
			phandle = <0x49>;
		};

		cpu@2 {
			device_type = "cpu";
			compatible = "arm,cortex-a7";
			enable-method = "psci";
			reg = <0x02>;
			cpufreq-data-v1 = <0x53>;
			cpu-idle-states = <0x54>;
			cpu-supply = <0x38>;
			phandle = <0x4b>;
		};

		cpu@3 {
			device_type = "cpu";
			compatible = "arm,cortex-a7";
			enable-method = "psci";
			reg = <0x03>;
			cpufreq-data-v1 = <0x53>;
			cpu-idle-states = <0x54>;
			cpu-supply = <0x38>;
			phandle = <0x4d>;
		};
	};

	idle-states {

		light_sleep {
			compatible = "sprd,pike2-idle-state";
			entry-latency-us = <0x14>;
			exit-latency-us = <0x0a>;
			min-residency-us = <0x32>;
			local-timer-stop;
			phandle = <0x54>;
		};

		heavy_sleep {
			compatible = "sprd,pike2-idle-state";
			entry-latency-us = <0x190>;
			exit-latency-us = <0x2bc>;
			min-residency-us = <0x4b0>;
			local-timer-stop;
			phandle = <0xcb>;
		};
	};

	cpufreq-clus0 {
		clocks = <0x09 0x0d 0x07 0x01 0x07 0x21>;
		clock-names = "core_clk\0low_freq_clk_parent\0high_freq_clk_parent";
		clock-latency = <0xc350>;
		sprd,cpu-gpu-share-volt;
		syscons = <0x11 0x3098 0xffffffff 0x11 0x309c 0xffffffff>;
		syscon-names = "gpu_target_volt\0cpu_target_volt";
		voltage-tolerance = <0x00>;
		default-efuse-blk-binning = <0x01>;
		sprd,efuse-blk-binning = <0x2b 0xf00>;
		nvmem-cells = <0x55>;
		nvmem-cell-names = "dvfs_bin";
		sprd,cpufreq-temp-threshold = <0x32>;
		operating-points = <0x13d620 0xf97b3 0x124f80 0xf1da1 0x118c30 0xee098 0x10c8e0 0xeafc4 0xf4240 0xe35b2 0xdbba0 0xdbba0 0xbb800 0xdbba0>;
		operating-points-0 = <0x13d620 0xf97b3 0x124f80 0xf1da1 0x118c30 0xee098 0x10c8e0 0xeafc4 0xf4240 0xe35b2 0xdbba0 0xdbba0 0xbb800 0xdbba0>;
		operating-points-1 = <0x13d620 0xe7ef0 0x124f80 0xe1d48 0x118c30 0xdec74 0x10c8e0 0xdbba0 0xf4240 0xdbba0 0xdbba0 0xdbba0 0xbb800 0xdbba0>;
		operating-points-2 = <0x13d620 0xf1da1 0x124f80 0xeafc4 0x118c30 0xe72bb 0x10c8e0 0xe35b2 0xf4240 0xdbba0 0xdbba0 0xdbba0 0xbb800 0xdbba0>;
		operating-points-3 = <0x13d620 0xf97b3 0x124f80 0xf1da1 0x118c30 0xee098 0x10c8e0 0xeafc4 0xf4240 0xe35b2 0xdbba0 0xdbba0 0xbb800 0xdbba0>;
		operating-points-4 = <0x13d620 0x100590 0x124f80 0xf97b3 0x118c30 0xf5aaa 0x10c8e0 0xf1da1 0xf4240 0xeafc4 0xdbba0 0xe35b2 0xbb800 0xdbba0>;
		operating-points-0-50 = <0x13d620 0xfe0f1 0x124f80 0xf5aaa 0x118c30 0xf116c 0x10c8e0 0xed463 0xf4240 0xe4e1c 0xdbba0 0xdbba0 0xbb800 0xdbba0>;
		operating-points-1-50 = <0x13d620 0xed463 0x124f80 0xe4e1c 0x118c30 0xe04de 0x10c8e0 0xdbba0 0xf4240 0xdbba0 0xdbba0 0xdbba0 0xbb800 0xdbba0>;
		operating-points-2-50 = <0x13d620 0xf7314 0x124f80 0xee098 0x118c30 0xe975a 0x10c8e0 0xe4e1c 0xf4240 0xdbba0 0xdbba0 0xdbba0 0xbb800 0xdbba0>;
		operating-points-3-50 = <0x13d620 0xfe0f1 0x124f80 0xf5aaa 0x118c30 0xf116c 0x10c8e0 0xed463 0xf4240 0xe4e1c 0xdbba0 0xdbba0 0xbb800 0xdbba0>;
		operating-points-4-50 = <0x124f80 0xfd4bc 0x118c30 0xf97b3 0x10c8e0 0xf4e75 0xf4240 0xec82e 0xdbba0 0xe41e7 0xbb800 0xdbba0>;
		phandle = <0x53>;
	};

	sprd-swdvfs {
		compatible = "sprd,pike2-swdvfs";
		phandle = <0xcc>;
	};

	psci {
		compatible = "arm,psci-1.0";
		method = "smc";
	};

	power-debug {
		compatible = "sprd,power-debug-pike2";
		sprd,enable = <0x01>;
		sprd,scan-interval = <0x1e>;
		sprd,sys-ap-ahb = <0x0e>;
		sprd,sys-ap-apb = <0x08>;
		sprd,sys-pmu-apb = <0x1b>;
		sprd,sys-aon-apb = <0x11>;
		sprd,sys-ap-intc = <0x3b 0x3c 0x3d 0x3e 0x56>;
		phandle = <0xcd>;
	};

	sprd-gsp {
		compatible = "sprd,gsp-lite_r2p0-pike2";
		core-cnt = <0x01>;
		io-cnt = <0x07>;
		cores = <0x57>;
		phandle = <0x72>;
	};

	interrupt-controller@12001000 {
		compatible = "arm,cortex-a15-gic\0arm,cortex-a9-gic";
		#interrupt-cells = <0x03>;
		#address-cells = <0x00>;
		interrupt-controller;
		reg = <0x12001000 0x1000 0x12002000 0x1000>;
		phandle = <0x01>;
	};

	timer {
		compatible = "arm,armv7-timer";
		interrupts = <0x01 0x0e 0xf08 0x01 0x0a 0xf08>;
		clock-frequency = <0x18cba80>;
		arm,no-tick-in-suspend;
		phandle = <0xce>;
	};

	pmu {
		compatible = "arm,cortex-a7-pmu";
		interrupts = <0x00 0x5c 0x04 0x00 0x5d 0x04 0x00 0x5e 0x04 0x00 0x5f 0x04>;
	};

	cpwcn_btwf {
		compatible = "sprd,integrate_marlin";
		sprd,name = "wcn_btwf";
		sprd,syscon-ap-apb = <0x11>;
		sprd,syscon-ap-pmu = <0x1b>;
		sprd,syscon-anlg-wrap-wcn = <0x58>;
		sprd,ctrl-probe-num = <0x02>;
		sprd,ctrl-reg = <0xd8 0xcc 0x2050 0x20b0 0x1338>;
		sprd,ctrl-mask = <0x03 0xffff 0x3000000 0x80 0x01>;
		sprd,ctrl-value = <0x00 0x8400 0x3000000 0x80 0x01>;
		sprd,ctrl-rw-offset = <0x00 0x00 0x2000 0x2000 0x1000>;
		sprd,ctrl-us-delay = <0x0a 0x0a 0x0a 0x3e8 0x0a>;
		sprd,ctrl-type = <0x00 0x00 0x01 0x01 0x01>;
		sprd,ctrl-shutdown-reg = <0x2338>;
		sprd,ctrl-shutdown-mask = <0x01>;
		sprd,ctrl-shutdown-value = <0x01>;
		sprd,ctrl-shutdown-rw-offset = <0x2000>;
		sprd,ctrl-shutdown-us-delay = <0x0a>;
		sprd,ctrl-shutdown-type = <0x01>;
		reg = <0x84000000 0x180000>;
		sprd,file-name = "/dev/block/platform/soc/soc:ap-ahb/20600000.sdio/by-name/wcnmodem";
		sprd,file-length = <0x178000>;
		memory_region = <0x59>;
		vddwcn-supply = <0x5a>;
		vddwifipa-supply = <0x5b>;
		#address-cells = <0x01>;
		#size-cells = <0x01>;
		nvmem-cells = <0x5c 0x5d 0x5e>;
		nvmem-cell-names = "wcn_efuse_blk0\0wcn_efuse_blk1\0wcn_efuse_blk2";
		phandle = <0xcf>;
	};

	cpwcn_gnss {
		compatible = "sprd,integrate_gnss";
		sprd,name = "wcn_gnss";
		sprd,syscon-ap-apb = <0x11>;
		sprd,syscon-ap-pmu = <0x1b>;
		sprd,syscon-anlg-wrap-wcn = <0x58>;
		sprd,ctrl-probe-num = <0x02>;
		sprd,ctrl-reg = <0xd8 0xcc 0x2050 0x20b0 0x1338>;
		sprd,ctrl-mask = <0x30000003 0xffff 0x3000000 0x80 0x02>;
		sprd,ctrl-value = <0x30000000 0x8400 0x3000000 0x80 0x02>;
		sprd,ctrl-rw-offset = <0x00 0x00 0x2000 0x2000 0x1000>;
		sprd,ctrl-us-delay = <0x0a 0x0a 0x0a 0x3e8 0x0a>;
		sprd,ctrl-type = <0x00 0x00 0x01 0x01 0x01>;
		sprd,ctrl-shutdown-reg = <0x2338>;
		sprd,ctrl-shutdown-mask = <0x02>;
		sprd,ctrl-shutdown-value = <0x02>;
		sprd,ctrl-shutdown-rw-offset = <0x2000>;
		sprd,ctrl-shutdown-us-delay = <0x0a>;
		sprd,ctrl-shutdown-type = <0x01>;
		reg = <0x84300000 0x100000>;
		sprd,file-name = "/dev/block/platform/soc/soc:ap-ahb/20600000.sdio/by-name/gpsgl";
		sprd,file-name-ext = "/dev/block/platform/soc/soc:ap-ahb/20600000.sdio/by-name/gpsbd";
		sprd,file-length = <0x100000>;
		memory_region = <0x5f>;
		vddwcn-supply = <0x5a>;
		#address-cells = <0x01>;
		#size-cells = <0x01>;
		nvmem-cells = <0x60 0x5d 0x5e>;
		nvmem-cell-names = "gnss_efuse_blk0\0gnss_efuse_blk1\0gnss_efuse_blk2";
		phandle = <0xd0>;
	};

	wcn_sipc {
		compatible = "sprd,sipc";

		sipc@84180000 {
			sprd,name = "sipc-wcn";
			sprd,dst = <0x03 0x04>;
			sprd,smem-info = <0x84180000 0x180000 0x180000>;
			phandle = <0xd1>;
		};

		sipc@8441b000 {
			sprd,name = "sipc-gnss";
			sprd,dst = <0x04 0x05>;
			sprd,smem-info = <0x8441b000 0x11b000 0x32000>;
			phandle = <0xd2>;
		};
	};

	wcn_spipe {
		compatible = "sprd,spipe";

		spipe_cpwcn {
			sprd,name = "spipe_wcn";
			sprd,dst = <0x03>;
			sprd,channel = <0x04>;
			sprd,ringnr = <0x10>;
			sprd,size-rxbuf = <0x2400>;
			sprd,size-txbuf = <0x2400>;
		};

		spipe_gnss {
			sprd,name = "sttygnss0";
			sprd,dst = <0x04>;
			sprd,channel = <0x04>;
			sprd,ringnr = <0x01>;
			sprd,size-rxbuf = <0x19000>;
			sprd,size-txbuf = <0xc800>;
		};
	};

	wcn_wifi_cmd {
		compatible = "sprd,swcnblk";
		sprd,name = "wcn_wifi_cmd";
		sprd,dst = <0x03>;
		sprd,channel = <0x07>;
		sprd,tx-blksize = <0x800>;
		sprd,tx-blknum = <0x04>;
		sprd,rx-blksize = <0x800>;
		sprd,rx-blknum = <0x10>;
	};

	wcn_wifi_data0 {
		compatible = "sprd,swcnblk";
		sprd,name = "wcn_wifi_data0";
		sprd,dst = <0x03>;
		sprd,channel = <0x08>;
		sprd,tx-blksize = <0x680>;
		sprd,tx-blknum = <0x40>;
		sprd,rx-blksize = <0x680>;
		sprd,rx-blknum = <0x100>;
	};

	wcn_wifi_data1 {
		compatible = "sprd,swcnblk";
		sprd,name = "wcn_wifi_data1";
		sprd,dst = <0x03>;
		sprd,channel = <0x09>;
		sprd,tx-blksize = <0x680>;
		sprd,tx-blknum = <0x40>;
		sprd,rx-blksize = <0x00>;
		sprd,rx-blknum = <0x00>;
	};

	wcn_bt {
		compatible = "sprd,wcn_internal_chip";
		sprd,name = "ttyBT";
		sprd,dst = <0x03>;
		sprd,channel = <0x04>;
		sprd,tx_bufid = <0x0b>;
		sprd,rx_bufid = <0x0a>;
	};

	wcn_fm {
		compatible = "sprd,wcn_internal_chip";
		sprd,name = "fm";
		sprd,dst = <0x03>;
		sprd,tx_channel = <0x04>;
		sprd,rx_channel = <0x04>;
		sprd,tx_bufid = <0x0e>;
		sprd,rx_bufid = <0x0d>;
	};

	gnss_common_ctl {
		compatible = "sprd,gnss_common_ctl";
		sprd,name = "gnss_common_ctl";
	};

	sprd-headset {
		compatible = "sprd,headset";
		status = "okay";
		jack-type = <0x00>;
		io-channels = <0x2c 0x14>;
		io-channel-names = "headmic_in_little";
		gpios = <0x2a 0x03 0x00 0x2a 0x07 0x00 0x2a 0x0b 0x00 0x2a 0x05 0x00 0x2a 0x0c 0x00>;
		gpio-trigger-levels = <0x01 0x01 0x01 0x01 0x01>;
		gpio-dbnc-intervals = <0x1e 0x64 0x64 0x64 0x64>;
		gpio-names = "button\0detect_l\0detect_h\0detect_mic\0detect_all";
		adc-threshold-3pole-detect = <0xb86>;
		sprd,adc-gnd = <0x1c2>;
		sprd,stable-value = <0x87a>;
		sprd,coefficient = <0xdff20>;
		irq-threshold-button = <0x09>;
		nvmem-cells = <0x61 0x62 0x63>;
		nvmem-cell-names = "protectbit\0auxadc\0headmic";
		sprd,spk-route-hp;
		phandle = <0x64>;

		headset-button@0 {
			adc-min = <0x00>;
			adc-max = <0x1ea>;
			code = <0xe2>;
		};

		headset-button@1 {
			adc-min = <0x21c>;
			adc-max = <0x3fc>;
			code = <0x73>;
		};

		headset-button@2 {
			adc-min = <0x442>;
			adc-max = <0x960>;
			code = <0x72>;
		};
	};

	sound@0 {
		compatible = "sprd,vbc-r1p0v3-codec-sc2721\0sprd,vbc-r1p0v3-codec-sc2731";
		status = "okay";
		sprd-audio-card,name = "sprdphone";
		sprd-audio-card,routing = "HPMIC Pin\0HP Mic Jack\0MIC Pin\0Mic Jack\0MIC2 Pin\0Aux Mic Jack\0HeadPhone Jack\0HP Pin\0Ext Spk\0HP Pin\0Ext Spk1\0HP Pin\0Ext Spk\0SPK Pin\0Ext Spk1\0SPK Pin\0Ext Ear\0EAR Pin\0Ext Ear\0SPK Pin\0Ext Ear\0HP Pin\0DMIC\0DMic Jack\0DMIC1\0DMic1 Jack\0Aud input\0AD Clk\0Aud input1\0AD Clk\0Aud input\0Digital ADCL Switch\0Aud input\0Digital ADCR Switch\0Aud input1\0Digital ADC1L Switch\0Aud input1\0Digital ADC1R Switch";
		sprd-audio-card,headset = <0x64>;
		sprd-audio-card,fm-open-src = <0x01>;
		sprd-audio-card,fm-hw-rate = <0x7d00>;
		sprd-audio-card,codec-replace-adc-rate = <0xbb80>;
		sprd,spk-ext-pa-info = <0x00 0x00 0x02 0x00>;
		sprd,spk-ext-pa-gpio = <0x65 0x3b 0x00>;
		phandle = <0xd3>;

		sprd-audio-card,dai-link@0 {

			plat {
				sound-dai = <0x66>;
			};

			cpu {
				sound-dai = <0x67 0x00>;
			};

			codec {
				sound-dai = <0x68 0x00>;
			};
		};

		sprd-audio-card,dai-link@1 {

			plat {
				sound-dai = <0x66>;
			};

			cpu {
				sound-dai = <0x69 0x00>;
			};

			codec {
				sound-dai = <0x68 0x01>;
			};
		};

		sprd-audio-card,dai-link@2 {

			plat {
				sound-dai = <0x66>;
			};

			cpu {
				sound-dai = <0x67 0x01>;
			};

			codec {
				sound-dai = <0x68 0x03>;
			};
		};

		sprd-audio-card,dai-link@3 {

			plat {
				sound-dai = <0x66>;
			};

			cpu {
				sound-dai = <0x69 0x01>;
			};

			codec {
				sound-dai = <0x68 0x04>;
			};
		};

		sprd-audio-card,dai-link@4 {
			ops = <0x00>;

			plat {
				sound-dai = <0x66>;
			};

			cpu {
				sound-dai = <0x67 0x02>;
			};

			codec {
				sound-dai = <0x68 0x05>;
			};
		};

		sprd-audio-card,dai-link@5 {

			plat {
				sound-dai = <0x66>;
			};

			cpu {
				sound-dai = <0x67 0x03>;
			};

			codec {
				sound-dai = <0x68 0x06>;
			};
		};
	};

	sound@1 {
		compatible = "sprd,i2s-null-codec";
		status = "okay";
		sprd-audio-card,name = "all-i2s";
		phandle = <0xd4>;

		sprd-audio-card,dai-link@0 {

			plat {
				sound-dai = <0x6a>;
			};

			cpu {
				sound-dai = <0x6b>;
			};

			codec {
				sound-dai = <0x00 0x00>;
			};
		};
	};

	chosen {
		stdout-path = "/soc/ap-apb/serial@70100000";
		bootargs = "earlycon=sprd_serial,0x70100000,115200n8 loglevel=1 console=ttyS1,115200n8 init=/init root=/dev/ram0 rw printk.devkmsg=on androidboot.boot_devices=soc/soc:ap-ahb/20600000.sdio";
		phandle = <0xd5>;
	};

	memory@80000000 {
		device_type = "memory";
		reg = <0x80000000 0x40000000>;
		phandle = <0xd6>;
	};

	extcon-gpio {
		compatible = "linux,extcon-usb-gpio";
		vbus-gpio = <0x2a 0x00 0x00>;
		id-gpio = <0x6c 0x04 0x00>;
		phandle = <0x1a>;
	};

	firmware {

		android {
			compatible = "android,firmware";

			vbmeta {
				compatible = "android,vbmeta";
				parts = "vbmeta,socko,odmko,boot,dtbo,w_modem,pm_sys,w_gdsp,vbmeta_hmdodm";
			};
		};
	};

	ion {
		compatible = "sprd,ion";
		#address-cells = <0x01>;
		#size-cells = <0x00>;
		phandle = <0xd7>;
	};

	reserved-memory {
		#address-cells = <0x01>;
		#size-cells = <0x01>;
		ranges;
		phandle = <0xd8>;

		warm-boot@0x81ff0000 {
			reg = <0x81ff0000 0x10000>;
			phandle = <0x6d>;
		};

		wcn-mem@84000000 {
			reg = <0x84000000 0x300000>;
			phandle = <0x59>;
		};

		gnss-mem@84300000 {
			reg = <0x84300000 0x15b000>;
			phandle = <0x5f>;
		};

		iq-mem@85400000 {
			compatible = "sprd,iq-mem";
			reg = <0x85400000 0x4000000>;
			phandle = <0x73>;
		};

		sipc-mem@89400000 {
			reg = <0x89400000 0x200000>;
			phandle = <0xd9>;
		};

		cp-modem@89600000 {
			reg = <0x89600000 0x2300000>;
			phandle = <0xda>;
		};

		sml-mem@94000000 {
			reg = <0x94000000 0x20000>;
			phandle = <0xdb>;
		};

		tos-mem@94020000 {
			reg = <0x94020000 0x2e0000>;
			phandle = <0xdc>;
		};

		logobuffer@9e000000 {
			reg = <0x9e000000 0x3f4800>;
			phandle = <0x10>;
		};
	};

	sprd-map-user {
		compatible = "sprd,map-user";
	};

	sprd-wlan {
		compatible = "sprd,sp7731e";
	};

	sprd_scale {
		compatible = "sprd,sprd_scale";
		iommus = <0x35>;
		status = "okay";
	};

	sprd_rotation {
		compatible = "sprd,sprd_rotation";
		sprd,cam-ahb-syscon = <0x31>;
		iommus = <0x35>;
		status = "okay";
	};

	resume_on_reboot {
		compatible = "sprd,memdisk";

		warm_boot {
			memory-region = <0x6d>;
			label = "warmboot";
		};
	};

	thermal-zones {
		phandle = <0xdd>;

		cpu-thmzone {
			polling-delay-passive = <0x64>;
			polling-delay = <0x3e8>;
			sustainable-power = <0x3e8>;
			thermal-sensors = <0x6e 0x00>;
			phandle = <0xde>;

			trips {

				trip-point@0 {
					temperature = <0x11170>;
					hysteresis = <0x3e8>;
					type = "passive";
					phandle = <0xdf>;
				};

				trip-point@1 {
					temperature = <0x14c08>;
					hysteresis = <0x3e8>;
					type = "passive";
					phandle = <0x6f>;
				};

				cpu_crit {
					temperature = <0x1adb0>;
					hysteresis = <0x7d0>;
					type = "critical";
					phandle = <0xe0>;
				};
			};

			cooling-maps {

				map0 {
					trip = <0x6f>;
					contribution = <0x400>;
					cooling-device = <0x70 0xffffffff 0xffffffff>;
				};
			};
		};
	};

	cooling-devices {

		cluster0-cooling {
			compatible = "sprd,cluster-cooling";
			#cooling-cells = <0x02>;
			sprd,efuse-block7 = <0x07>;
			sprd,efuse-block15 = <0x0f>;
			sprd,leak-core = <0x02 0x55 0x74d>;
			sprd,leak-cluster = <0x02 0x55 0x9dc>;
			sprd,core-temp-scale = <0x1e 0xfffff572 0x22e7a 0xffec36f3>;
			sprd,core-voltage-scale = <0x2d2 0xfffffa4d 0x4a6 0xfffffec4>;
			sprd,cluster-temp-scale = <0x1e 0xfffff5cf 0x22242 0xffed98c2>;
			sprd,cluster-voltage-scale = <0x266 0xfffffbaa 0x335 0xffffff44>;
			sprd,efuse-switch = <0x00>;
			sprd,hotplug-period = <0x0a>;
			sprd,min-cpufreq = <0xbb800>;
			sprd,min-cpunum = <0x04>;
			sprd,core-base = <0x473>;
			sprd,cluster-base = <0xabf>;
			sprd,dynamic-core = <0x330 0x300 0x384>;
			sprd,dynamic-cluster = <0x0f 0x300 0x384>;
			phandle = <0x70>;
		};
	};

	display-subsystem {
		compatible = "sprd,display-subsystem";
		ports = <0x71>;
		gsp = <0x72>;
	};

	sprd-iq {
		compatible = "sprd,iq";
		sprd,region = <0x73>;
		sprd,mapping-offs = <0x00>;
	};

	sprd-hotplug {
		enable-dynamic-hotplug;
	};

	scene-frequency {
		compatible = "sprd,dfs";
		freq-num = <0x04>;
		phandle = <0xe1>;
	};

	autotest {
		compatible = "sprd,autotest";
		sprd,pinctrl = <0x74>;
		phandle = <0xe2>;
	};

	interrupt-controller {
		compatible = "android,CustomIPI";
		#interrupt-cells = <0x01>;
		interrupt-controller;
		phandle = <0x75>;
	};

	trusty {
		compatible = "android,trusty-smc-v1";

		irq {
			compatible = "android,trusty-irq-v1";
			interrupt-templates = <0x75 0x00 0x01 0x01 0x01 0x00 0x01 0x01 0x00 0x00>;
			interrupt-ranges = <0x00 0x0f 0x00 0x10 0x1f 0x01 0x20 0xdf 0x02>;
		};

		virtio {
			compatible = "android,trusty-virtio-v1";
		};

		log {
			compatible = "android,trusty-log-v1";
		};
	};

	__symbols__ {
		soc = "/soc";
		ap_ahb_regs = "/soc/syscon@20e00000";
		anlg_wrap_wcn_regs = "/soc/syscon@33100000";
		aon_intc_regs = "/soc/syscon@40200000";
		pmu_apb_regs = "/soc/syscon@402b0000";
		aon_apb_regs = "/soc/syscon@402e0000";
		anlg_phy_g1_regs = "/soc/syscon@40350000";
		anlg_phy_g2_regs = "/soc/syscon@40353000";
		anlg_phy_g3_regs = "/soc/syscon@40356000";
		anlg_phy_g5_regs = "/soc/syscon@40359000";
		gpu_ahb_regs = "/soc/syscon@60100000";
		mm_ahb_regs = "/soc/syscon@60d00000";
		ap_apb_regs = "/soc/syscon@71300000";
		intc0_controller = "/soc/syscon@71400000";
		intc1_controller = "/soc/syscon@71500000";
		intc2_controller = "/soc/syscon@71600000";
		intc3_controller = "/soc/syscon@71700000";
		uart0 = "/soc/ap-apb/serial@70000000";
		uart1 = "/soc/ap-apb/serial@70100000";
		i2c0 = "/soc/ap-apb/i2c@70500000";
		i2c1 = "/soc/ap-apb/i2c@70600000";
		i2c2 = "/soc/ap-apb/i2c@70700000";
		spi0 = "/soc/ap-apb/spi@70a00000";
		spi1 = "/soc/ap-apb/spi@70b00000";
		i2s0 = "/soc/ap-apb/i2s@70d00000";
		ap_dma = "/soc/ap-ahb/dma-controller@20100000";
		usb = "/soc/ap-ahb/usb@20200000";
		sdio3 = "/soc/ap-ahb/sdio@20600000";
		sdio0 = "/soc/ap-ahb/sdio@20300000";
		dpu = "/soc/ap-ahb/dpu@20800000";
		dpu_port = "/soc/ap-ahb/dpu@20800000/port";
		dpu_out = "/soc/ap-ahb/dpu@20800000/port/endpoint";
		iommu_dispc = "/soc/ap-ahb/iommu@20800800";
		dsi = "/soc/ap-ahb/dsi@21800000";
		dsi_out = "/soc/ap-ahb/dsi@21800000/ports/port@0/endpoint";
		dsi_in = "/soc/ap-ahb/dsi@21800000/ports/port@1/endpoint";
		panel = "/soc/ap-ahb/dsi@21800000/panel";
		panel_in = "/soc/ap-ahb/dsi@21800000/panel/port@1/endpoint";
		dphy = "/soc/ap-ahb/dphy";
		dphy_out = "/soc/ap-ahb/dphy/port@0/endpoint";
		dphy_in = "/soc/ap-ahb/dphy/port@1/endpoint";
		gsp_core0 = "/soc/ap-ahb/gsp@20a00000";
		iommu_gsp = "/soc/ap-ahb/iommu@20a00804";
		hsphy = "/soc/ap-ahb/hsphy@20e00000";
		sprd_audio_codec_dig = "/soc/aon/audio-codec@40000000";
		vbc = "/soc/aon/vbc@40020000";
		aon_sysfrt = "/soc/aon/timer@40040000";
		hwlock = "/soc/aon/hwspinlock@40060000";
		aon_mailbox = "/soc/aon/mailbox@400a0000";
		aon_dma = "/soc/aon/dma-controller@40100000";
		pwms = "/soc/aon/pwm@40260000";
		adi_bus = "/soc/aon/spi@403c0000";
		sc2720_pmic = "/soc/aon/spi@403c0000/pmic@0";
		pmic_wdt = "/soc/aon/spi@403c0000/pmic@0/watchdog@40";
		pmic_flash = "/soc/aon/spi@403c0000/pmic@0/flash@1f4";
		pmic_eic = "/soc/aon/spi@403c0000/pmic@0/gpio-controller@280";
		pmic_efuse = "/soc/aon/spi@403c0000/pmic@0/efuse@300";
		fgu_calib = "/soc/aon/spi@403c0000/pmic@0/efuse@300/calib@6";
		cccv_calib = "/soc/aon/spi@403c0000/pmic@0/efuse@300/calib@1a";
		adc_bcal = "/soc/aon/spi@403c0000/pmic@0/efuse@300/calib@24";
		adc_scal = "/soc/aon/spi@403c0000/pmic@0/efuse@300/calib@26";
		hp_efuse_protectbit = "/soc/aon/spi@403c0000/pmic@0/efuse@300/calib@0";
		hp_efuse_auxadc = "/soc/aon/spi@403c0000/pmic@0/efuse@300/calib@28";
		hp_efuse_headmic = "/soc/aon/spi@403c0000/pmic@0/efuse@300/calib@2c";
		pmic_adc = "/soc/aon/spi@403c0000/pmic@0/adc@404";
		sprd_audio_codec_ana = "/soc/aon/spi@403c0000/pmic@0/audio-codec@700";
		pmic_fgu = "/soc/aon/spi@403c0000/pmic@0/fgu@a00";
		vddcore = "/soc/aon/spi@403c0000/pmic@0/power-controller@c00/DCDC_CORE";
		vddgen = "/soc/aon/spi@403c0000/pmic@0/power-controller@c00/DCDC_GEN";
		vddwpa = "/soc/aon/spi@403c0000/pmic@0/power-controller@c00/DCDC_WPA";
		avdd18 = "/soc/aon/spi@403c0000/pmic@0/power-controller@c00/LDO_AVDD18";
		vddcamio = "/soc/aon/spi@403c0000/pmic@0/power-controller@c00/LDO_VDDCAMIO";
		vddrf18a = "/soc/aon/spi@403c0000/pmic@0/power-controller@c00/LDO_VDDRF18A";
		vddrf18b = "/soc/aon/spi@403c0000/pmic@0/power-controller@c00/LDO_VDDRF18B";
		vddcamd = "/soc/aon/spi@403c0000/pmic@0/power-controller@c00/LDO_VDDCAMD";
		vddcon = "/soc/aon/spi@403c0000/pmic@0/power-controller@c00/LDO_VDDCON";
		vddmem = "/soc/aon/spi@403c0000/pmic@0/power-controller@c00/LDO_MEM";
		vddsim0 = "/soc/aon/spi@403c0000/pmic@0/power-controller@c00/LDO_VDDSIM0";
		vddsim1 = "/soc/aon/spi@403c0000/pmic@0/power-controller@c00/LDO_VDDSIM1";
		vddsim2 = "/soc/aon/spi@403c0000/pmic@0/power-controller@c00/LDO_VDDSIM2";
		vddcama = "/soc/aon/spi@403c0000/pmic@0/power-controller@c00/LDO_VDDCAMA";
		vddcammot = "/soc/aon/spi@403c0000/pmic@0/power-controller@c00/LDO_VDDCAMMOT";
		vddemmccore = "/soc/aon/spi@403c0000/pmic@0/power-controller@c00/LDO_VDDEMMCCORE";
		vddsdcore = "/soc/aon/spi@403c0000/pmic@0/power-controller@c00/LDO_VDDSDCORE";
		vddsdio = "/soc/aon/spi@403c0000/pmic@0/power-controller@c00/LDO_VDDSDIO";
		vdd28 = "/soc/aon/spi@403c0000/pmic@0/power-controller@c00/LDO_VDD28";
		vddwifipa = "/soc/aon/spi@403c0000/pmic@0/power-controller@c00/LDO_VDDWIFIPA";
		vdddcxo = "/soc/aon/spi@403c0000/pmic@0/power-controller@c00/LDO_VDDDCXO";
		vddusb33 = "/soc/aon/spi@403c0000/pmic@0/power-controller@c00/LDO_VDDUSB33";
		pmic_charger = "/soc/aon/spi@403c0000/pmic@0/charger@e0c";
		eic_debounce = "/soc/aon/gpio@40210000";
		eic_latch = "/soc/aon/gpio@40210080";
		eic_async = "/soc/aon/gpio@402100a0";
		eic_sync = "/soc/aon/gpio@402100c0";
		ap_efuse = "/soc/aon/efuse@40240000";
		cthm_sign = "/soc/aon/efuse@40240000/cthm-sign@20";
		cthm_ratio = "/soc/aon/efuse@40240000/cthm-ratio@20";
		cthm_delta = "/soc/aon/efuse@40240000/cthm-delta@21";
		wcn_alpha = "/soc/aon/efuse@40240000/wcn-alpha@8";
		wcn_beta = "/soc/aon/efuse@40240000/wcn-beta@c";
		wcn_gamma = "/soc/aon/efuse@40240000/wcn-gamma@10";
		wcn_delta = "/soc/aon/efuse@40240000/wcn-delta@20";
		dvfs_bin_cpu0 = "/soc/aon/efuse@40240000/dvfs-bin-cpu0@1d";
		ap_gpio = "/soc/aon/gpio@40280000";
		pin_controller = "/soc/aon/pinctrl@402a0000";
		ap_iis0_0 = "/soc/aon/pinctrl@402a0000/ap-iis0-0";
		tgdsp_iis0_0 = "/soc/aon/pinctrl@402a0000/tgdsp-iis0-0";
		pubcp_iis0_0 = "/soc/aon/pinctrl@402a0000/pubcp-iis0-0";
		vbc_iis2_0 = "/soc/aon/pinctrl@402a0000/vbc-iis2-0";
		ap_iis0_1 = "/soc/aon/pinctrl@402a0000/ap-iis0-1";
		tgdsp_iis0_1 = "/soc/aon/pinctrl@402a0000/tgdsp-iis0-1";
		pubcp_iis0_1 = "/soc/aon/pinctrl@402a0000/pubcp-iis0-1";
		vbc_iis1_1 = "/soc/aon/pinctrl@402a0000/vbc-iis1-1";
		cpu_thm = "/soc/aon/thermal@402f0000";
		djtag = "/soc/aon/djtag@40340000";
		cam_domain = "/soc/mm/cam-domain";
		mipi_csi_phy0 = "/soc/mm/mipi-csi-phy0";
		dcam = "/soc/mm/dcam@60800000";
		iommu_dcam = "/soc/mm/iommu@60800200";
		isp = "/soc/mm/isp@60a00000";
		iommu_isp = "/soc/mm/iommu@60a00800";
		jpg = "/soc/mm/jpeg-codec@60b00000";
		iommu_jpg = "/soc/mm/iommu@60b00100";
		csi0 = "/soc/mm/csi@60c00000";
		gpu = "/soc/mm/gpu@60000000";
		vsp = "/soc/mm/video-codec@60900000";
		iommu_vsp = "/soc/mm/iommu@60901140";
		dmc_controller = "/soc/pub/dmc-controller@30000000";
		funnel_soc = "/soc/funnel-soc@10001000";
		funnel_soc_out_port = "/soc/funnel-soc@10001000/ports/port@0/endpoint";
		funnel_soc_in_port = "/soc/funnel-soc@10001000/ports/port@1/endpoint";
		etb = "/soc/tmc-etb@10003000";
		etb_in = "/soc/tmc-etb@10003000/port/endpoint";
		ts = "/soc/cs-ts@10009000";
		funnel_core = "/soc/funnel-core@10220000";
		funnel_core_out_port = "/soc/funnel-core@10220000/ports/port@0/endpoint";
		funnel_core_in_port0 = "/soc/funnel-core@10220000/ports/port@1/endpoint";
		funnel_core_in_port1 = "/soc/funnel-core@10220000/ports/port@2/endpoint";
		funnel_core_in_port2 = "/soc/funnel-core@10220000/ports/port@3/endpoint";
		funnel_core_in_port3 = "/soc/funnel-core@10220000/ports/port@4/endpoint";
		etm_core0 = "/soc/etm-core0@1025c000";
		etm0_out = "/soc/etm-core0@1025c000/port/endpoint";
		etm_core1 = "/soc/etm-core1@1025d000";
		etm1_out = "/soc/etm-core1@1025d000/port/endpoint";
		etm_core2 = "/soc/etm-core2@1025e000";
		etm2_out = "/soc/etm-core2@1025e000/port/endpoint";
		etm_core3 = "/soc/etm-core3@1025f000";
		etm3_out = "/soc/etm-core3@1025f000/port/endpoint";
		pmu_gate = "/soc/pmu-gate";
		pll = "/soc/pll";
		apahb_gate = "/soc/apahb-gate";
		ap_clk = "/soc/clock-controller@21500000";
		aon_clk = "/soc/clock-controller@402d0000";
		aonapb_gate = "/soc/aonapb-gate";
		gpu_clk = "/soc/clock-controller@60100000";
		mm_clk = "/soc/clock-controller@60e00000";
		mm_gate = "/soc/mm-gate";
		apapb_gate = "/soc/apapb-gate";
		sprd_pcm = "/sprd-pcm-audio";
		sprd_pcm_iis = "/sprd-pcm-iis";
		vaudio = "/vaudio";
		ext_26m = "/ext-26m";
		ext_26m_cp = "/ext-26m-cp";
		ext_26m_aud = "/ext-26m-aud";
		ext_32k = "/ext-32k";
		bbpll = "/bbpll";
		scproc_pubpm = "/scproc-pubcp/scproc@50800000";
		scproc_pubcp = "/scproc-pubcp/scproc@5000d000";
		sipc0 = "/sprd-sipc/sipc@89400000";
		sipc1 = "/sprd-sipc/sipc@5000b000";
		seth_ch7 = "/seth@0";
		seth_ch8 = "/seth@1";
		seth_ch9 = "/seth@2";
		seth_ch18 = "/seth@3";
		seth_ch19 = "/seth@4";
		seth_ch20 = "/seth@5";
		seth_ch24 = "/seth@6";
		seth_ch25 = "/seth@7";
		seth_ch26 = "/seth@8";
		seth_ch27 = "/seth@9";
		seth_ch28 = "/seth@10";
		seth_ch29 = "/seth@11";
		seth_ch30 = "/seth@12";
		seth_ch31 = "/seth@13";
		cpu0 = "/cpus/cpu@0";
		cpu1 = "/cpus/cpu@1";
		cpu2 = "/cpus/cpu@2";
		cpu3 = "/cpus/cpu@3";
		LIGHT_SLEEP = "/idle-states/light_sleep";
		HEAVY_SLEEP = "/idle-states/heavy_sleep";
		cpufreq_clus0 = "/cpufreq-clus0";
		sprd_swdvfs = "/sprd-swdvfs";
		power = "/power-debug";
		gsp = "/sprd-gsp";
		gic = "/interrupt-controller@12001000";
		arch_timer = "/timer";
		wcn_btwf = "/cpwcn_btwf";
		wcn_gnss = "/cpwcn_gnss";
		sipc2 = "/wcn_sipc/sipc@84180000";
		sipc3 = "/wcn_sipc/sipc@8441b000";
		sprd_headset = "/sprd-headset";
		sound_vbc_r1p0v3_sprd_codec = "/sound@0";
		sound_sprd_ap_alliis = "/sound@1";
		chosen = "/chosen";
		memory = "/memory@80000000";
		extcon_gpio = "/extcon-gpio";
		ion = "/ion";
		reserved_memory = "/reserved-memory";
		warm_boot_reserved = "/reserved-memory/warm-boot@0x81ff0000";
		wcn_reserved = "/reserved-memory/wcn-mem@84000000";
		gnss_reserved = "/reserved-memory/gnss-mem@84300000";
		iq_reserved = "/reserved-memory/iq-mem@85400000";
		smem_reserved = "/reserved-memory/sipc-mem@89400000";
		cp_reserved = "/reserved-memory/cp-modem@89600000";
		sml_reserved = "/reserved-memory/sml-mem@94000000";
		tos_reserved = "/reserved-memory/tos-mem@94020000";
		logo_reserved = "/reserved-memory/logobuffer@9e000000";
		thm_zone = "/thermal-zones";
		cpu_thmzone = "/thermal-zones/cpu-thmzone";
		cpu_threshold = "/thermal-zones/cpu-thmzone/trips/trip-point@0";
		cpu_target = "/thermal-zones/cpu-thmzone/trips/trip-point@1";
		cpu_crit = "/thermal-zones/cpu-thmzone/trips/cpu_crit";
		cluster0_cooling = "/cooling-devices/cluster0-cooling";
		ddr_dfs = "/scene-frequency";
		autotest = "/autotest";
		ipi = "/interrupt-controller";
	};
};
